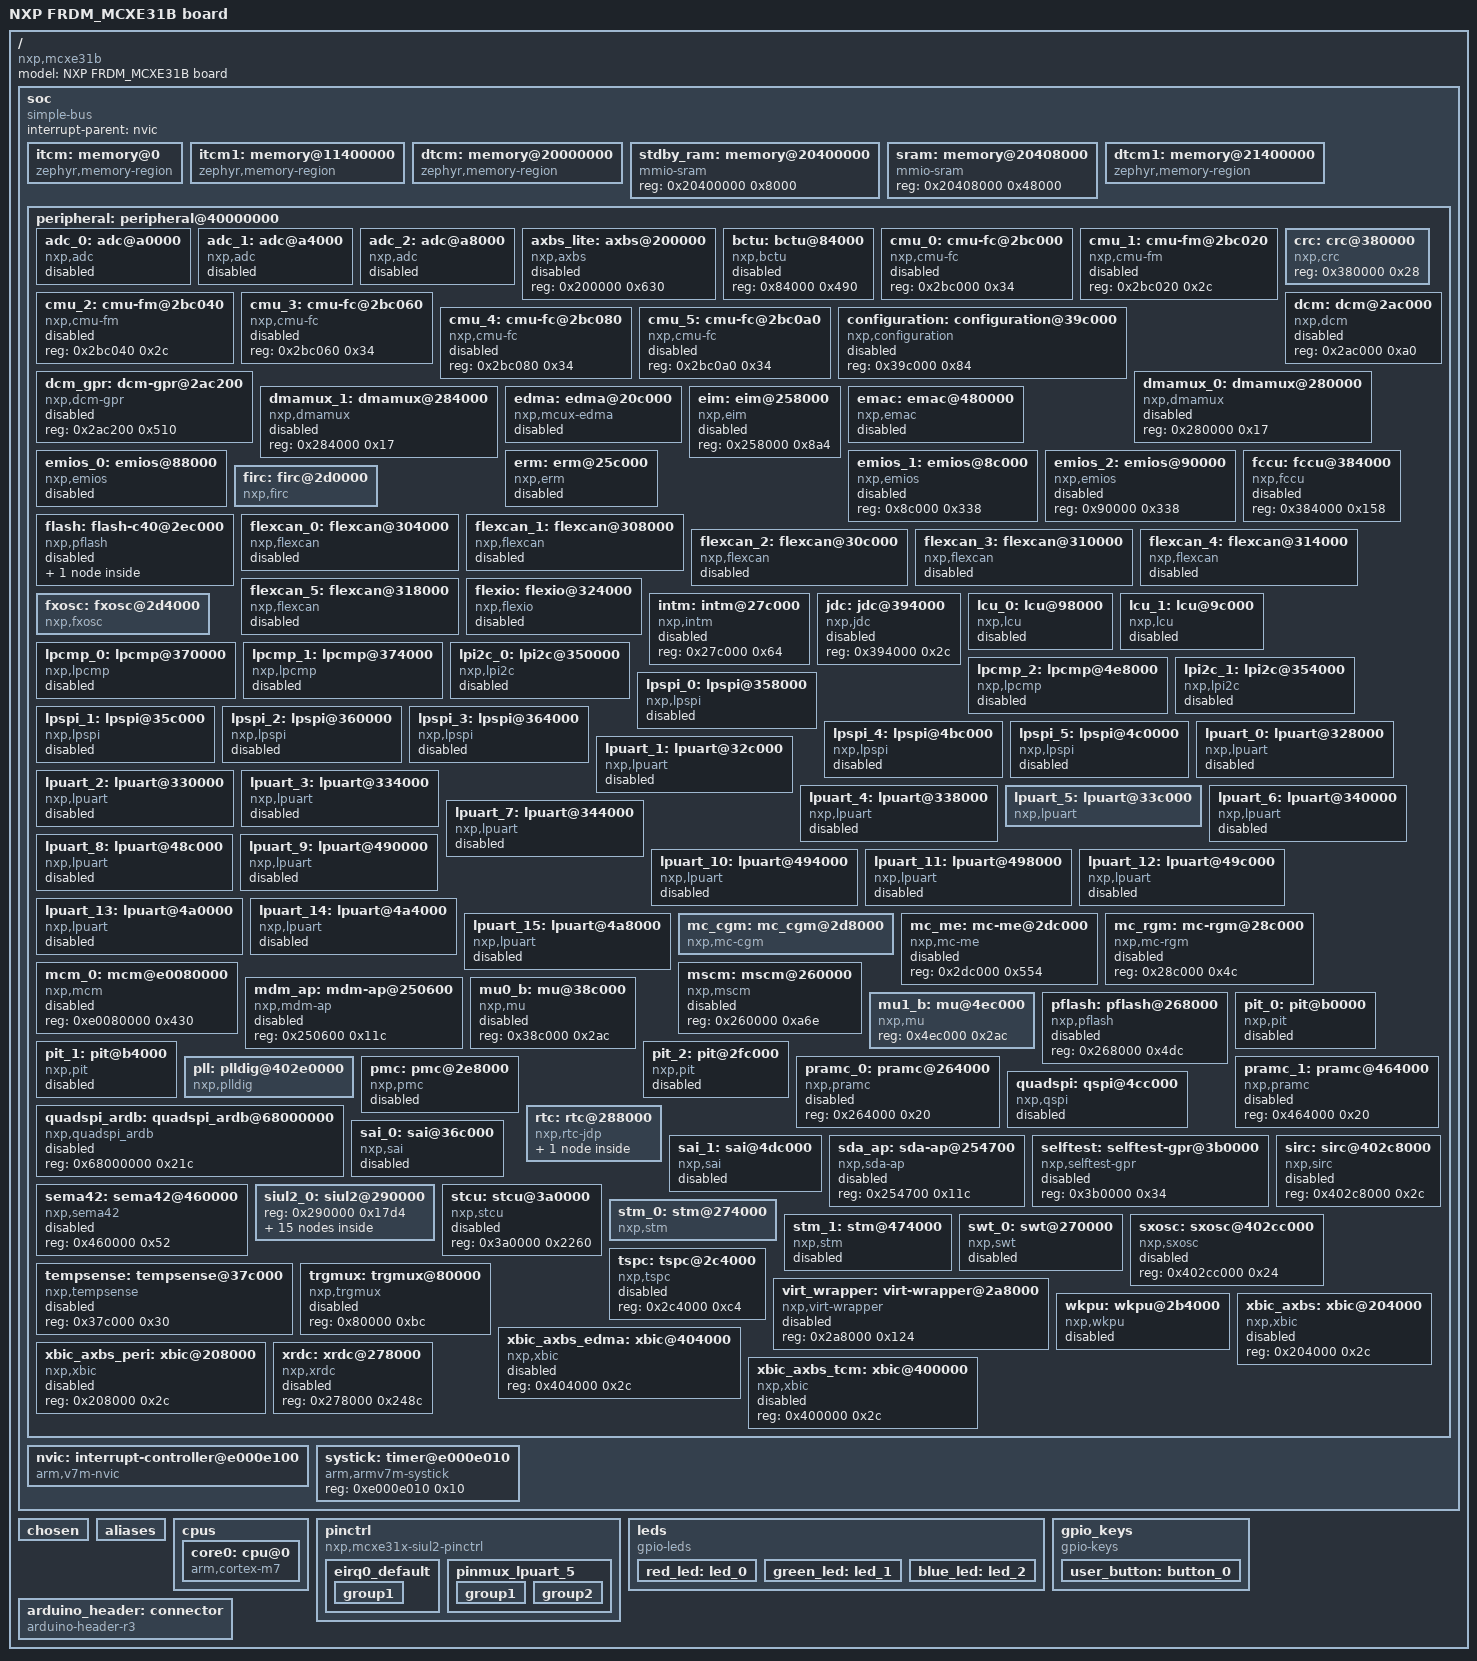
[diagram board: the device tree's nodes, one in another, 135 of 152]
/dts-v1/;

/* node '/' defined in zephyr/dts/arm/nxp/nxp_mcxe31b.dtsi:10 */
/ {
	#address-cells = < 0x1 >;         /* in zephyr/dts/common/skeleton.dtsi:10 */
	#size-cells = < 0x1 >;            /* in zephyr/dts/common/skeleton.dtsi:11 */
	model = "NXP FRDM_MCXE31B board"; /* in zephyr/boards/nxp/frdm_mcxe31b/frdm_mcxe31b.dts:16 */
	compatible = "nxp,mcxe31b";       /* in zephyr/boards/nxp/frdm_mcxe31b/frdm_mcxe31b.dts:17 */

	/* node '/soc' defined in zephyr/dts/arm/nxp/nxp_mcxe31b.dtsi:11 */
	soc {
		#address-cells = < 0x1 >;     /* in zephyr/dts/arm/armv7-m.dtsi:7 */
		#size-cells = < 0x1 >;        /* in zephyr/dts/arm/armv7-m.dtsi:8 */
		compatible = "simple-bus";    /* in zephyr/dts/arm/armv7-m.dtsi:9 */
		interrupt-parent = < &nvic >; /* in zephyr/dts/arm/armv7-m.dtsi:10 */
		ranges;                       /* in zephyr/dts/arm/armv7-m.dtsi:11 */

		/* node '/soc/memory@0' defined in zephyr/dts/arm/nxp/nxp_mcxe31b.dtsi:12 */
		itcm: memory@0 {
			compatible = "zephyr,memory-region",
			             "mmio-sram";            /* in zephyr/dts/arm/nxp/nxp_mcxe31b.dtsi:13 */
			reg = < 0x0 0x8000 >;                /* in zephyr/dts/arm/nxp/nxp_mcxe31b.dtsi:14 */
			zephyr,memory-region = "ITCM";       /* in zephyr/dts/arm/nxp/nxp_mcxe31b.dtsi:15 */
		};

		/* node '/soc/memory@11400000' defined in zephyr/dts/arm/nxp/nxp_mcxe31b.dtsi:18 */
		itcm1: memory@11400000 {
			compatible = "zephyr,memory-region",
			             "mmio-sram";            /* in zephyr/dts/arm/nxp/nxp_mcxe31b.dtsi:19 */
			reg = < 0x11400000 0x8000 >;         /* in zephyr/dts/arm/nxp/nxp_mcxe31b.dtsi:20 */
			zephyr,memory-region = "ITCM1";      /* in zephyr/dts/arm/nxp/nxp_mcxe31b.dtsi:21 */
		};

		/* node '/soc/memory@20000000' defined in zephyr/dts/arm/nxp/nxp_mcxe31b.dtsi:24 */
		dtcm: memory@20000000 {
			compatible = "zephyr,memory-region",
			             "mmio-sram";            /* in zephyr/dts/arm/nxp/nxp_mcxe31b.dtsi:25 */
			reg = < 0x20000000 0x10000 >;        /* in zephyr/dts/arm/nxp/nxp_mcxe31b.dtsi:26 */
			zephyr,memory-region = "DTCM";       /* in zephyr/dts/arm/nxp/nxp_mcxe31b.dtsi:27 */
		};

		/* node '/soc/memory@20400000' defined in zephyr/dts/arm/nxp/nxp_mcxe31b.dtsi:31 */
		stdby_ram: memory@20400000 {
			compatible = "mmio-sram";    /* in zephyr/dts/arm/nxp/nxp_mcxe31b.dtsi:32 */
			reg = < 0x20400000 0x8000 >; /* in zephyr/dts/arm/nxp/nxp_mcxe31b.dtsi:33 */
		};

		/* node '/soc/memory@20408000' defined in zephyr/dts/arm/nxp/nxp_mcxe31b.dtsi:37 */
		sram: memory@20408000 {
			compatible = "mmio-sram";     /* in zephyr/dts/arm/nxp/nxp_mcxe31b.dtsi:38 */
			reg = < 0x20408000 0x48000 >; /* in zephyr/dts/arm/nxp/nxp_mcxe31b.dtsi:39 */
		};

		/* node '/soc/memory@21400000' defined in zephyr/dts/arm/nxp/nxp_mcxe31b.dtsi:42 */
		dtcm1: memory@21400000 {
			compatible = "zephyr,memory-region",
			             "mmio-sram";            /* in zephyr/dts/arm/nxp/nxp_mcxe31b.dtsi:43 */
			reg = < 0x21400000 0x10000 >;        /* in zephyr/dts/arm/nxp/nxp_mcxe31b.dtsi:44 */
			zephyr,memory-region = "DTCM1";      /* in zephyr/dts/arm/nxp/nxp_mcxe31b.dtsi:45 */
		};

		/* node '/soc/peripheral@40000000' defined in zephyr/dts/arm/nxp/nxp_mcxe31b.dtsi:48 */
		peripheral: peripheral@40000000 {
			ranges = < 0x0 0x40000000 0x10000000 >; /* in zephyr/dts/arm/nxp/nxp_mcxe31b.dtsi:49 */
			#address-cells = < 0x1 >;               /* in zephyr/dts/arm/nxp/nxp_mcxe31x_common.dtsi:31 */
			#size-cells = < 0x1 >;                  /* in zephyr/dts/arm/nxp/nxp_mcxe31x_common.dtsi:32 */

			/* node '/soc/peripheral@40000000/adc@a0000' defined in zephyr/dts/arm/nxp/nxp_mcxe31x_common.dtsi:34 */
			adc_0: adc@a0000 {
				compatible = "nxp,adc";    /* in zephyr/dts/arm/nxp/nxp_mcxe31x_common.dtsi:35 */
				reg = < 0xa0000 0x3d4 >;   /* in zephyr/dts/arm/nxp/nxp_mcxe31x_common.dtsi:36 */
				interrupts = < 0xb4 0x0 >; /* in zephyr/dts/arm/nxp/nxp_mcxe31x_common.dtsi:37 */
				status = "disabled";       /* in zephyr/dts/arm/nxp/nxp_mcxe31x_common.dtsi:38 */
			};

			/* node '/soc/peripheral@40000000/adc@a4000' defined in zephyr/dts/arm/nxp/nxp_mcxe31x_common.dtsi:41 */
			adc_1: adc@a4000 {
				compatible = "nxp,adc";    /* in zephyr/dts/arm/nxp/nxp_mcxe31x_common.dtsi:42 */
				reg = < 0xa4000 0x3d4 >;   /* in zephyr/dts/arm/nxp/nxp_mcxe31x_common.dtsi:43 */
				interrupts = < 0xb5 0x0 >; /* in zephyr/dts/arm/nxp/nxp_mcxe31x_common.dtsi:44 */
				status = "disabled";       /* in zephyr/dts/arm/nxp/nxp_mcxe31x_common.dtsi:45 */
			};

			/* node '/soc/peripheral@40000000/adc@a8000' defined in zephyr/dts/arm/nxp/nxp_mcxe31x_common.dtsi:48 */
			adc_2: adc@a8000 {
				compatible = "nxp,adc";    /* in zephyr/dts/arm/nxp/nxp_mcxe31x_common.dtsi:49 */
				reg = < 0xa8000 0x3d4 >;   /* in zephyr/dts/arm/nxp/nxp_mcxe31x_common.dtsi:50 */
				interrupts = < 0xb6 0x0 >; /* in zephyr/dts/arm/nxp/nxp_mcxe31x_common.dtsi:51 */
				status = "disabled";       /* in zephyr/dts/arm/nxp/nxp_mcxe31x_common.dtsi:52 */
			};

			/* node '/soc/peripheral@40000000/axbs@200000' defined in zephyr/dts/arm/nxp/nxp_mcxe31x_common.dtsi:55 */
			axbs_lite: axbs@200000 {
				compatible = "nxp,axbs";  /* in zephyr/dts/arm/nxp/nxp_mcxe31x_common.dtsi:56 */
				reg = < 0x200000 0x630 >; /* in zephyr/dts/arm/nxp/nxp_mcxe31x_common.dtsi:57 */
				status = "disabled";      /* in zephyr/dts/arm/nxp/nxp_mcxe31x_common.dtsi:58 */
			};

			/* node '/soc/peripheral@40000000/bctu@84000' defined in zephyr/dts/arm/nxp/nxp_mcxe31x_common.dtsi:61 */
			bctu: bctu@84000 {
				compatible = "nxp,bctu"; /* in zephyr/dts/arm/nxp/nxp_mcxe31x_common.dtsi:62 */
				reg = < 0x84000 0x490 >; /* in zephyr/dts/arm/nxp/nxp_mcxe31x_common.dtsi:63 */
				status = "disabled";     /* in zephyr/dts/arm/nxp/nxp_mcxe31x_common.dtsi:64 */
			};

			/* node '/soc/peripheral@40000000/cmu-fc@2bc000' defined in zephyr/dts/arm/nxp/nxp_mcxe31x_common.dtsi:67 */
			cmu_0: cmu-fc@2bc000 {
				compatible = "nxp,cmu-fc"; /* in zephyr/dts/arm/nxp/nxp_mcxe31x_common.dtsi:68 */
				reg = < 0x2bc000 0x34 >;   /* in zephyr/dts/arm/nxp/nxp_mcxe31x_common.dtsi:69 */
				status = "disabled";       /* in zephyr/dts/arm/nxp/nxp_mcxe31x_common.dtsi:70 */
			};

			/* node '/soc/peripheral@40000000/cmu-fm@2bc020' defined in zephyr/dts/arm/nxp/nxp_mcxe31x_common.dtsi:73 */
			cmu_1: cmu-fm@2bc020 {
				compatible = "nxp,cmu-fm"; /* in zephyr/dts/arm/nxp/nxp_mcxe31x_common.dtsi:74 */
				reg = < 0x2bc020 0x2c >;   /* in zephyr/dts/arm/nxp/nxp_mcxe31x_common.dtsi:75 */
				status = "disabled";       /* in zephyr/dts/arm/nxp/nxp_mcxe31x_common.dtsi:76 */
			};

			/* node '/soc/peripheral@40000000/cmu-fm@2bc040' defined in zephyr/dts/arm/nxp/nxp_mcxe31x_common.dtsi:79 */
			cmu_2: cmu-fm@2bc040 {
				compatible = "nxp,cmu-fm"; /* in zephyr/dts/arm/nxp/nxp_mcxe31x_common.dtsi:80 */
				reg = < 0x2bc040 0x2c >;   /* in zephyr/dts/arm/nxp/nxp_mcxe31x_common.dtsi:81 */
				status = "disabled";       /* in zephyr/dts/arm/nxp/nxp_mcxe31x_common.dtsi:82 */
			};

			/* node '/soc/peripheral@40000000/cmu-fc@2bc060' defined in zephyr/dts/arm/nxp/nxp_mcxe31x_common.dtsi:85 */
			cmu_3: cmu-fc@2bc060 {
				compatible = "nxp,cmu-fc"; /* in zephyr/dts/arm/nxp/nxp_mcxe31x_common.dtsi:86 */
				reg = < 0x2bc060 0x34 >;   /* in zephyr/dts/arm/nxp/nxp_mcxe31x_common.dtsi:87 */
				status = "disabled";       /* in zephyr/dts/arm/nxp/nxp_mcxe31x_common.dtsi:88 */
			};

			/* node '/soc/peripheral@40000000/cmu-fc@2bc080' defined in zephyr/dts/arm/nxp/nxp_mcxe31x_common.dtsi:91 */
			cmu_4: cmu-fc@2bc080 {
				compatible = "nxp,cmu-fc"; /* in zephyr/dts/arm/nxp/nxp_mcxe31x_common.dtsi:92 */
				reg = < 0x2bc080 0x34 >;   /* in zephyr/dts/arm/nxp/nxp_mcxe31x_common.dtsi:93 */
				status = "disabled";       /* in zephyr/dts/arm/nxp/nxp_mcxe31x_common.dtsi:94 */
			};

			/* node '/soc/peripheral@40000000/cmu-fc@2bc0a0' defined in zephyr/dts/arm/nxp/nxp_mcxe31x_common.dtsi:97 */
			cmu_5: cmu-fc@2bc0a0 {
				compatible = "nxp,cmu-fc"; /* in zephyr/dts/arm/nxp/nxp_mcxe31x_common.dtsi:98 */
				reg = < 0x2bc0a0 0x34 >;   /* in zephyr/dts/arm/nxp/nxp_mcxe31x_common.dtsi:99 */
				status = "disabled";       /* in zephyr/dts/arm/nxp/nxp_mcxe31x_common.dtsi:100 */
			};

			/* node '/soc/peripheral@40000000/configuration@39c000' defined in zephyr/dts/arm/nxp/nxp_mcxe31x_common.dtsi:103 */
			configuration: configuration@39c000 {
				compatible = "nxp,configuration"; /* in zephyr/dts/arm/nxp/nxp_mcxe31x_common.dtsi:104 */
				reg = < 0x39c000 0x84 >;          /* in zephyr/dts/arm/nxp/nxp_mcxe31x_common.dtsi:105 */
				status = "disabled";              /* in zephyr/dts/arm/nxp/nxp_mcxe31x_common.dtsi:106 */
			};

			/* node '/soc/peripheral@40000000/crc@380000' defined in zephyr/dts/arm/nxp/nxp_mcxe31x_common.dtsi:109 */
			crc: crc@380000 {
				compatible = "nxp,crc";  /* in zephyr/dts/arm/nxp/nxp_mcxe31x_common.dtsi:110 */
				reg = < 0x380000 0x28 >; /* in zephyr/dts/arm/nxp/nxp_mcxe31x_common.dtsi:111 */
			};

			/* node '/soc/peripheral@40000000/dcm@2ac000' defined in zephyr/dts/arm/nxp/nxp_mcxe31x_common.dtsi:114 */
			dcm: dcm@2ac000 {
				compatible = "nxp,dcm";  /* in zephyr/dts/arm/nxp/nxp_mcxe31x_common.dtsi:115 */
				reg = < 0x2ac000 0xa0 >; /* in zephyr/dts/arm/nxp/nxp_mcxe31x_common.dtsi:116 */
				status = "disabled";     /* in zephyr/dts/arm/nxp/nxp_mcxe31x_common.dtsi:117 */
			};

			/* node '/soc/peripheral@40000000/dcm-gpr@2ac200' defined in zephyr/dts/arm/nxp/nxp_mcxe31x_common.dtsi:120 */
			dcm_gpr: dcm-gpr@2ac200 {
				compatible = "nxp,dcm-gpr"; /* in zephyr/dts/arm/nxp/nxp_mcxe31x_common.dtsi:121 */
				reg = < 0x2ac200 0x510 >;   /* in zephyr/dts/arm/nxp/nxp_mcxe31x_common.dtsi:122 */
				status = "disabled";        /* in zephyr/dts/arm/nxp/nxp_mcxe31x_common.dtsi:123 */
			};

			/* node '/soc/peripheral@40000000/dmamux@280000' defined in zephyr/dts/arm/nxp/nxp_mcxe31x_common.dtsi:126 */
			dmamux_0: dmamux@280000 {
				compatible = "nxp,dmamux"; /* in zephyr/dts/arm/nxp/nxp_mcxe31x_common.dtsi:127 */
				reg = < 0x280000 0x17 >;   /* in zephyr/dts/arm/nxp/nxp_mcxe31x_common.dtsi:128 */
				status = "disabled";       /* in zephyr/dts/arm/nxp/nxp_mcxe31x_common.dtsi:129 */
			};

			/* node '/soc/peripheral@40000000/dmamux@284000' defined in zephyr/dts/arm/nxp/nxp_mcxe31x_common.dtsi:132 */
			dmamux_1: dmamux@284000 {
				compatible = "nxp,dmamux"; /* in zephyr/dts/arm/nxp/nxp_mcxe31x_common.dtsi:133 */
				reg = < 0x284000 0x17 >;   /* in zephyr/dts/arm/nxp/nxp_mcxe31x_common.dtsi:134 */
				status = "disabled";       /* in zephyr/dts/arm/nxp/nxp_mcxe31x_common.dtsi:135 */
			};

			/* node '/soc/peripheral@40000000/edma@20c000' defined in zephyr/dts/arm/nxp/nxp_mcxe31x_common.dtsi:138 */
			edma: edma@20c000 {
				#dma-cells = < 0x2 >;         /* in zephyr/dts/arm/nxp/nxp_mcxe31x_common.dtsi:139 */
				compatible = "nxp,mcux-edma"; /* in zephyr/dts/arm/nxp/nxp_mcxe31x_common.dtsi:140 */
				reg = < 0x20c000 0x19c >;     /* in zephyr/dts/arm/nxp/nxp_mcxe31x_common.dtsi:141 */
				dma-channels = < 0x20 >;      /* in zephyr/dts/arm/nxp/nxp_mcxe31x_common.dtsi:142 */
				dma-requests = < 0x80 >;      /* in zephyr/dts/arm/nxp/nxp_mcxe31x_common.dtsi:143 */
				interrupts = < 0x4 0x0 >,
				             < 0x5 0x0 >,
				             < 0x6 0x0 >,
				             < 0x7 0x0 >,
				             < 0x8 0x0 >,
				             < 0x9 0x0 >,
				             < 0xa 0x0 >,
				             < 0xb 0x0 >,
				             < 0xc 0x0 >,
				             < 0xd 0x0 >,
				             < 0xe 0x0 >,
				             < 0xf 0x0 >,
				             < 0x10 0x0 >,
				             < 0x11 0x0 >,
				             < 0x12 0x0 >,
				             < 0x13 0x0 >,
				             < 0x14 0x0 >,
				             < 0x15 0x0 >,
				             < 0x16 0x0 >,
				             < 0x17 0x0 >,
				             < 0x18 0x0 >,
				             < 0x19 0x0 >,
				             < 0x1a 0x0 >,
				             < 0x1b 0x0 >,
				             < 0x1c 0x0 >,
				             < 0x1d 0x0 >,
				             < 0x1e 0x0 >,
				             < 0x1f 0x0 >,
				             < 0x20 0x0 >,
				             < 0x21 0x0 >,
				             < 0x22 0x0 >,
				             < 0x23 0x0 >;    /* in zephyr/dts/arm/nxp/nxp_mcxe31x_common.dtsi:144 */
				status = "disabled";          /* in zephyr/dts/arm/nxp/nxp_mcxe31x_common.dtsi:152 */
				phandle = < 0x4 >;            /* in zephyr/boards/nxp/frdm_mcxe31b/frdm_mcxe31b.dts:109 */
			};

			/* node '/soc/peripheral@40000000/eim@258000' defined in zephyr/dts/arm/nxp/nxp_mcxe31x_common.dtsi:155 */
			eim: eim@258000 {
				compatible = "nxp,eim";   /* in zephyr/dts/arm/nxp/nxp_mcxe31x_common.dtsi:156 */
				reg = < 0x258000 0x8a4 >; /* in zephyr/dts/arm/nxp/nxp_mcxe31x_common.dtsi:157 */
				status = "disabled";      /* in zephyr/dts/arm/nxp/nxp_mcxe31x_common.dtsi:158 */
			};

			/* node '/soc/peripheral@40000000/emac@480000' defined in zephyr/dts/arm/nxp/nxp_mcxe31x_common.dtsi:161 */
			emac: emac@480000 {
				compatible = "nxp,emac";   /* in zephyr/dts/arm/nxp/nxp_mcxe31x_common.dtsi:162 */
				reg = < 0x480000 0x120c >; /* in zephyr/dts/arm/nxp/nxp_mcxe31x_common.dtsi:163 */
				interrupts = < 0x69 0x0 >; /* in zephyr/dts/arm/nxp/nxp_mcxe31x_common.dtsi:164 */
				status = "disabled";       /* in zephyr/dts/arm/nxp/nxp_mcxe31x_common.dtsi:165 */
			};

			/* node '/soc/peripheral@40000000/emios@88000' defined in zephyr/dts/arm/nxp/nxp_mcxe31x_common.dtsi:168 */
			emios_0: emios@88000 {
				compatible = "nxp,emios";     /* in zephyr/dts/arm/nxp/nxp_mcxe31x_common.dtsi:169 */
				reg = < 0x88000 0x338 >;      /* in zephyr/dts/arm/nxp/nxp_mcxe31x_common.dtsi:170 */
				interrupts = < 0x3d 0x0 >,
				             < 0x3e 0x0 >,
				             < 0x3f 0x0 >,
				             < 0x40 0x0 >,
				             < 0x41 0x0 >,
				             < 0x42 0x0 >;    /* in zephyr/dts/arm/nxp/nxp_mcxe31x_common.dtsi:171 */
				interrupt-names = "emios0-2",
				                  "emios0-3",
				                  "emios0-4",
				                  "emios0-5",
				                  "emios0-6",
				                  "emios0-7"; /* in zephyr/dts/arm/nxp/nxp_mcxe31x_common.dtsi:173 */
				status = "disabled";          /* in zephyr/dts/arm/nxp/nxp_mcxe31x_common.dtsi:175 */
			};

			/* node '/soc/peripheral@40000000/emios@8c000' defined in zephyr/dts/arm/nxp/nxp_mcxe31x_common.dtsi:178 */
			emios_1: emios@8c000 {
				compatible = "nxp,emios"; /* in zephyr/dts/arm/nxp/nxp_mcxe31x_common.dtsi:179 */
				reg = < 0x8c000 0x338 >;  /* in zephyr/dts/arm/nxp/nxp_mcxe31x_common.dtsi:180 */
				status = "disabled";      /* in zephyr/dts/arm/nxp/nxp_mcxe31x_common.dtsi:181 */
			};

			/* node '/soc/peripheral@40000000/emios@90000' defined in zephyr/dts/arm/nxp/nxp_mcxe31x_common.dtsi:184 */
			emios_2: emios@90000 {
				compatible = "nxp,emios"; /* in zephyr/dts/arm/nxp/nxp_mcxe31x_common.dtsi:185 */
				reg = < 0x90000 0x338 >;  /* in zephyr/dts/arm/nxp/nxp_mcxe31x_common.dtsi:186 */
				status = "disabled";      /* in zephyr/dts/arm/nxp/nxp_mcxe31x_common.dtsi:187 */
			};

			/* node '/soc/peripheral@40000000/erm@25c000' defined in zephyr/dts/arm/nxp/nxp_mcxe31x_common.dtsi:190 */
			erm: erm@25c000 {
				compatible = "nxp,erm";    /* in zephyr/dts/arm/nxp/nxp_mcxe31x_common.dtsi:191 */
				reg = < 0x25c000 0x258 >;  /* in zephyr/dts/arm/nxp/nxp_mcxe31x_common.dtsi:192 */
				interrupts = < 0x24 0x0 >,
				             < 0x25 0x0 >; /* in zephyr/dts/arm/nxp/nxp_mcxe31x_common.dtsi:193 */
				interrupt-names = "erm-0",
				                  "erm-1"; /* in zephyr/dts/arm/nxp/nxp_mcxe31x_common.dtsi:194 */
				status = "disabled";       /* in zephyr/dts/arm/nxp/nxp_mcxe31x_common.dtsi:195 */
			};

			/* node '/soc/peripheral@40000000/fccu@384000' defined in zephyr/dts/arm/nxp/nxp_mcxe31x_common.dtsi:198 */
			fccu: fccu@384000 {
				compatible = "nxp,fccu";  /* in zephyr/dts/arm/nxp/nxp_mcxe31x_common.dtsi:199 */
				reg = < 0x384000 0x158 >; /* in zephyr/dts/arm/nxp/nxp_mcxe31x_common.dtsi:200 */
				status = "disabled";      /* in zephyr/dts/arm/nxp/nxp_mcxe31x_common.dtsi:201 */
			};

			/* node '/soc/peripheral@40000000/firc@2d0000' defined in zephyr/dts/arm/nxp/nxp_mcxe31x_common.dtsi:204 */
			firc: firc@2d0000 {
				compatible = "nxp,firc"; /* in zephyr/dts/arm/nxp/nxp_mcxe31x_common.dtsi:205 */
				reg = < 0x2d0000 0x28 >; /* in zephyr/dts/arm/nxp/nxp_mcxe31x_common.dtsi:206 */
				status = "okay";         /* in zephyr/boards/nxp/frdm_mcxe31b/frdm_mcxe31b.dts:132 */
				firc-div = "UnDiv";      /* in zephyr/boards/nxp/frdm_mcxe31b/frdm_mcxe31b.dts:133 */
			};

			/* node '/soc/peripheral@40000000/flash-c40@2ec000' defined in zephyr/dts/arm/nxp/nxp_mcxe31x_common.dtsi:210 */
			flash: flash-c40@2ec000 {
				compatible = "nxp,pflash";   /* in zephyr/dts/arm/nxp/nxp_mcxe31x_common.dtsi:211 */
				reg = < 0x2ec000 0x19c >;    /* in zephyr/dts/arm/nxp/nxp_mcxe31x_common.dtsi:212 */
				interrupts = < 0x30 0x0 >,
				             < 0x31 0x0 >,
				             < 0x32 0x0 >;   /* in zephyr/dts/arm/nxp/nxp_mcxe31x_common.dtsi:213 */
				interrupt-names = "flash-0",
				                  "flash-1",
				                  "flash-2"; /* in zephyr/dts/arm/nxp/nxp_mcxe31x_common.dtsi:214 */
				#address-cells = < 0x1 >;    /* in zephyr/dts/arm/nxp/nxp_mcxe31x_common.dtsi:215 */
				#size-cells = < 0x1 >;       /* in zephyr/dts/arm/nxp/nxp_mcxe31x_common.dtsi:216 */
				status = "disabled";         /* in zephyr/dts/arm/nxp/nxp_mcxe31x_common.dtsi:217 */

				/* node '/soc/peripheral@40000000/flash-c40@2ec000/memory@400000' defined in zephyr/dts/arm/nxp/nxp_mcxe31x_common.dtsi:219 */
				program_flash: memory@400000 {
					compatible = "soc-nv-flash"; /* in zephyr/dts/arm/nxp/nxp_mcxe31x_common.dtsi:220 */
					reg = < 0x400000 0x400000 >; /* in zephyr/dts/arm/nxp/nxp_mcxe31x_common.dtsi:221 */
				};
			};

			/* node '/soc/peripheral@40000000/flexcan@304000' defined in zephyr/dts/arm/nxp/nxp_mcxe31x_common.dtsi:225 */
			flexcan_0: flexcan@304000 {
				compatible = "nxp,flexcan";     /* in zephyr/dts/arm/nxp/nxp_mcxe31x_common.dtsi:226 */
				reg = < 0x304000 0x321c >;      /* in zephyr/dts/arm/nxp/nxp_mcxe31x_common.dtsi:227 */
				interrupts = < 0x6d 0x0 >,
				             < 0x6e 0x0 >,
				             < 0x6f 0x0 >,
				             < 0x70 0x0 >;      /* in zephyr/dts/arm/nxp/nxp_mcxe31x_common.dtsi:228 */
				interrupt-names = "flexcan0-0",
				                  "flexcan0-1",
				                  "flexcan0-2",
				                  "flexcan0-3"; /* in zephyr/dts/arm/nxp/nxp_mcxe31x_common.dtsi:229 */
				clocks = < &mc_cgm 0x2400 >;    /* in zephyr/dts/arm/nxp/nxp_mcxe31x_common.dtsi:230 */
				clk-source = < 0x0 >;           /* in zephyr/dts/arm/nxp/nxp_mcxe31x_common.dtsi:231 */
				status = "disabled";            /* in zephyr/dts/arm/nxp/nxp_mcxe31x_common.dtsi:232 */
			};

			/* node '/soc/peripheral@40000000/flexcan@308000' defined in zephyr/dts/arm/nxp/nxp_mcxe31x_common.dtsi:235 */
			flexcan_1: flexcan@308000 {
				compatible = "nxp,flexcan";     /* in zephyr/dts/arm/nxp/nxp_mcxe31x_common.dtsi:236 */
				reg = < 0x308000 0xd4c >;       /* in zephyr/dts/arm/nxp/nxp_mcxe31x_common.dtsi:237 */
				interrupts = < 0x71 0x0 >,
				             < 0x72 0x0 >,
				             < 0x73 0x0 >;      /* in zephyr/dts/arm/nxp/nxp_mcxe31x_common.dtsi:238 */
				interrupt-names = "flexcan1-0",
				                  "flexcan1-1",
				                  "flexcan1-2"; /* in zephyr/dts/arm/nxp/nxp_mcxe31x_common.dtsi:239 */
				clocks = < &mc_cgm 0x2401 >;    /* in zephyr/dts/arm/nxp/nxp_mcxe31x_common.dtsi:240 */
				clk-source = < 0x0 >;           /* in zephyr/dts/arm/nxp/nxp_mcxe31x_common.dtsi:241 */
				status = "disabled";            /* in zephyr/dts/arm/nxp/nxp_mcxe31x_common.dtsi:242 */
			};

			/* node '/soc/peripheral@40000000/flexcan@30c000' defined in zephyr/dts/arm/nxp/nxp_mcxe31x_common.dtsi:245 */
			flexcan_2: flexcan@30c000 {
				compatible = "nxp,flexcan";     /* in zephyr/dts/arm/nxp/nxp_mcxe31x_common.dtsi:246 */
				reg = < 0x30c000 0xd4c >;       /* in zephyr/dts/arm/nxp/nxp_mcxe31x_common.dtsi:247 */
				interrupts = < 0x74 0x0 >,
				             < 0x75 0x0 >,
				             < 0x76 0x0 >;      /* in zephyr/dts/arm/nxp/nxp_mcxe31x_common.dtsi:248 */
				interrupt-names = "flexcan2-0",
				                  "flexcan2-1",
				                  "flexcan2-2"; /* in zephyr/dts/arm/nxp/nxp_mcxe31x_common.dtsi:249 */
				clocks = < &mc_cgm 0x2402 >;    /* in zephyr/dts/arm/nxp/nxp_mcxe31x_common.dtsi:250 */
				clk-source = < 0x0 >;           /* in zephyr/dts/arm/nxp/nxp_mcxe31x_common.dtsi:251 */
				status = "disabled";            /* in zephyr/dts/arm/nxp/nxp_mcxe31x_common.dtsi:252 */
			};

			/* node '/soc/peripheral@40000000/flexcan@310000' defined in zephyr/dts/arm/nxp/nxp_mcxe31x_common.dtsi:255 */
			flexcan_3: flexcan@310000 {
				compatible = "nxp,flexcan";     /* in zephyr/dts/arm/nxp/nxp_mcxe31x_common.dtsi:256 */
				reg = < 0x310000 0xccc >;       /* in zephyr/dts/arm/nxp/nxp_mcxe31x_common.dtsi:257 */
				interrupts = < 0x77 0x0 >,
				             < 0x78 0x0 >;      /* in zephyr/dts/arm/nxp/nxp_mcxe31x_common.dtsi:258 */
				interrupt-names = "flexcan3-0",
				                  "flexcan3-1"; /* in zephyr/dts/arm/nxp/nxp_mcxe31x_common.dtsi:259 */
				clocks = < &mc_cgm 0x2403 >;    /* in zephyr/dts/arm/nxp/nxp_mcxe31x_common.dtsi:260 */
				clk-source = < 0x0 >;           /* in zephyr/dts/arm/nxp/nxp_mcxe31x_common.dtsi:261 */
				status = "disabled";            /* in zephyr/dts/arm/nxp/nxp_mcxe31x_common.dtsi:262 */
			};

			/* node '/soc/peripheral@40000000/flexcan@314000' defined in zephyr/dts/arm/nxp/nxp_mcxe31x_common.dtsi:265 */
			flexcan_4: flexcan@314000 {
				compatible = "nxp,flexcan";     /* in zephyr/dts/arm/nxp/nxp_mcxe31x_common.dtsi:266 */
				reg = < 0x314000 0xccc >;       /* in zephyr/dts/arm/nxp/nxp_mcxe31x_common.dtsi:267 */
				interrupts = < 0x79 0x0 >,
				             < 0x7a 0x0 >;      /* in zephyr/dts/arm/nxp/nxp_mcxe31x_common.dtsi:268 */
				interrupt-names = "flexcan4-0",
				                  "flexcan4-1"; /* in zephyr/dts/arm/nxp/nxp_mcxe31x_common.dtsi:269 */
				clocks = < &mc_cgm 0x2404 >;    /* in zephyr/dts/arm/nxp/nxp_mcxe31x_common.dtsi:270 */
				clk-source = < 0x0 >;           /* in zephyr/dts/arm/nxp/nxp_mcxe31x_common.dtsi:271 */
				status = "disabled";            /* in zephyr/dts/arm/nxp/nxp_mcxe31x_common.dtsi:272 */
			};

			/* node '/soc/peripheral@40000000/flexcan@318000' defined in zephyr/dts/arm/nxp/nxp_mcxe31x_common.dtsi:275 */
			flexcan_5: flexcan@318000 {
				compatible = "nxp,flexcan";     /* in zephyr/dts/arm/nxp/nxp_mcxe31x_common.dtsi:276 */
				reg = < 0x318000 0xccc >;       /* in zephyr/dts/arm/nxp/nxp_mcxe31x_common.dtsi:277 */
				interrupts = < 0x7b 0x0 >,
				             < 0x7c 0x0 >;      /* in zephyr/dts/arm/nxp/nxp_mcxe31x_common.dtsi:278 */
				interrupt-names = "flexcan5-0",
				                  "flexcan5-1"; /* in zephyr/dts/arm/nxp/nxp_mcxe31x_common.dtsi:279 */
				clocks = < &mc_cgm 0x2405 >;    /* in zephyr/dts/arm/nxp/nxp_mcxe31x_common.dtsi:280 */
				clk-source = < 0x0 >;           /* in zephyr/dts/arm/nxp/nxp_mcxe31x_common.dtsi:281 */
				status = "disabled";            /* in zephyr/dts/arm/nxp/nxp_mcxe31x_common.dtsi:282 */
			};

			/* node '/soc/peripheral@40000000/flexio@324000' defined in zephyr/dts/arm/nxp/nxp_mcxe31x_common.dtsi:285 */
			flexio: flexio@324000 {
				compatible = "nxp,flexio";   /* in zephyr/dts/arm/nxp/nxp_mcxe31x_common.dtsi:286 */
				reg = < 0x324000 0x93c >;    /* in zephyr/dts/arm/nxp/nxp_mcxe31x_common.dtsi:287 */
				interrupts = < 0x8b 0x0 >;   /* in zephyr/dts/arm/nxp/nxp_mcxe31x_common.dtsi:288 */
				clocks = < &mc_cgm 0x2500 >; /* in zephyr/dts/arm/nxp/nxp_mcxe31x_common.dtsi:289 */
				status = "disabled";         /* in zephyr/dts/arm/nxp/nxp_mcxe31x_common.dtsi:290 */
			};

			/* node '/soc/peripheral@40000000/fxosc@2d4000' defined in zephyr/dts/arm/nxp/nxp_mcxe31x_common.dtsi:293 */
			fxosc: fxosc@2d4000 {
				compatible = "nxp,fxosc"; /* in zephyr/dts/arm/nxp/nxp_mcxe31x_common.dtsi:294 */
				reg = < 0x2d4000 0x24 >;  /* in zephyr/dts/arm/nxp/nxp_mcxe31x_common.dtsi:295 */
				status = "okay";          /* in zephyr/boards/nxp/frdm_mcxe31b/frdm_mcxe31b.dts:137 */
				freq = < 0xf42400 >;      /* in zephyr/boards/nxp/frdm_mcxe31b/frdm_mcxe31b.dts:138 */
				workmode = "crystal";     /* in zephyr/boards/nxp/frdm_mcxe31b/frdm_mcxe31b.dts:139 */
				delay = < 0x31 >;         /* in zephyr/boards/nxp/frdm_mcxe31b/frdm_mcxe31b.dts:140 */
				overdrive = < 0xc >;      /* in zephyr/boards/nxp/frdm_mcxe31b/frdm_mcxe31b.dts:141 */
			};

			/* node '/soc/peripheral@40000000/intm@27c000' defined in zephyr/dts/arm/nxp/nxp_mcxe31x_common.dtsi:299 */
			intm: intm@27c000 {
				compatible = "nxp,intm"; /* in zephyr/dts/arm/nxp/nxp_mcxe31x_common.dtsi:300 */
				reg = < 0x27c000 0x64 >; /* in zephyr/dts/arm/nxp/nxp_mcxe31x_common.dtsi:301 */
				status = "disabled";     /* in zephyr/dts/arm/nxp/nxp_mcxe31x_common.dtsi:302 */
			};

			/* node '/soc/peripheral@40000000/jdc@394000' defined in zephyr/dts/arm/nxp/nxp_mcxe31x_common.dtsi:305 */
			jdc: jdc@394000 {
				compatible = "nxp,jdc";  /* in zephyr/dts/arm/nxp/nxp_mcxe31x_common.dtsi:306 */
				reg = < 0x394000 0x2c >; /* in zephyr/dts/arm/nxp/nxp_mcxe31x_common.dtsi:307 */
				status = "disabled";     /* in zephyr/dts/arm/nxp/nxp_mcxe31x_common.dtsi:308 */
			};

			/* node '/soc/peripheral@40000000/lcu@98000' defined in zephyr/dts/arm/nxp/nxp_mcxe31x_common.dtsi:311 */
			lcu_0: lcu@98000 {
				compatible = "nxp,lcu";    /* in zephyr/dts/arm/nxp/nxp_mcxe31x_common.dtsi:312 */
				reg = < 0x98000 0x2c8 >;   /* in zephyr/dts/arm/nxp/nxp_mcxe31x_common.dtsi:313 */
				interrupts = < 0x5c 0x0 >; /* in zephyr/dts/arm/nxp/nxp_mcxe31x_common.dtsi:314 */
				status = "disabled";       /* in zephyr/dts/arm/nxp/nxp_mcxe31x_common.dtsi:315 */
			};

			/* node '/soc/peripheral@40000000/lcu@9c000' defined in zephyr/dts/arm/nxp/nxp_mcxe31x_common.dtsi:318 */
			lcu_1: lcu@9c000 {
				compatible = "nxp,lcu";    /* in zephyr/dts/arm/nxp/nxp_mcxe31x_common.dtsi:319 */
				reg = < 0x9c000 0x2c8 >;   /* in zephyr/dts/arm/nxp/nxp_mcxe31x_common.dtsi:320 */
				interrupts = < 0x5d 0x0 >; /* in zephyr/dts/arm/nxp/nxp_mcxe31x_common.dtsi:321 */
				status = "disabled";       /* in zephyr/dts/arm/nxp/nxp_mcxe31x_common.dtsi:322 */
			};

			/* node '/soc/peripheral@40000000/lpcmp@370000' defined in zephyr/dts/arm/nxp/nxp_mcxe31x_common.dtsi:325 */
			lpcmp_0: lpcmp@370000 {
				compatible = "nxp,lpcmp";  /* in zephyr/dts/arm/nxp/nxp_mcxe31x_common.dtsi:326 */
				reg = < 0x370000 0x50 >;   /* in zephyr/dts/arm/nxp/nxp_mcxe31x_common.dtsi:327 */
				interrupts = < 0xb7 0x0 >; /* in zephyr/dts/arm/nxp/nxp_mcxe31x_common.dtsi:328 */
				status = "disabled";       /* in zephyr/dts/arm/nxp/nxp_mcxe31x_common.dtsi:329 */
			};

			/* node '/soc/peripheral@40000000/lpcmp@374000' defined in zephyr/dts/arm/nxp/nxp_mcxe31x_common.dtsi:332 */
			lpcmp_1: lpcmp@374000 {
				compatible = "nxp,lpcmp";  /* in zephyr/dts/arm/nxp/nxp_mcxe31x_common.dtsi:333 */
				reg = < 0x374000 0x50 >;   /* in zephyr/dts/arm/nxp/nxp_mcxe31x_common.dtsi:334 */
				interrupts = < 0xb8 0x0 >; /* in zephyr/dts/arm/nxp/nxp_mcxe31x_common.dtsi:335 */
				status = "disabled";       /* in zephyr/dts/arm/nxp/nxp_mcxe31x_common.dtsi:336 */
			};

			/* node '/soc/peripheral@40000000/lpcmp@4e8000' defined in zephyr/dts/arm/nxp/nxp_mcxe31x_common.dtsi:339 */
			lpcmp_2: lpcmp@4e8000 {
				compatible = "nxp,lpcmp";  /* in zephyr/dts/arm/nxp/nxp_mcxe31x_common.dtsi:340 */
				reg = < 0x4e8000 0x50 >;   /* in zephyr/dts/arm/nxp/nxp_mcxe31x_common.dtsi:341 */
				interrupts = < 0xb9 0x0 >; /* in zephyr/dts/arm/nxp/nxp_mcxe31x_common.dtsi:342 */
				status = "disabled";       /* in zephyr/dts/arm/nxp/nxp_mcxe31x_common.dtsi:343 */
			};

			/* node '/soc/peripheral@40000000/lpi2c@350000' defined in zephyr/dts/arm/nxp/nxp_mcxe31x_common.dtsi:346 */
			lpi2c_0: lpi2c@350000 {
				compatible = "nxp,lpi2c";    /* in zephyr/dts/arm/nxp/nxp_mcxe31x_common.dtsi:347 */
				reg = < 0x350000 0x190 >;    /* in zephyr/dts/arm/nxp/nxp_mcxe31x_common.dtsi:348 */
				interrupts = < 0xa1 0x0 >;   /* in zephyr/dts/arm/nxp/nxp_mcxe31x_common.dtsi:349 */
				clocks = < &mc_cgm 0x2600 >; /* in zephyr/dts/arm/nxp/nxp_mcxe31x_common.dtsi:350 */
				#address-cells = < 0x1 >;    /* in zephyr/dts/arm/nxp/nxp_mcxe31x_common.dtsi:351 */
				#size-cells = < 0x0 >;       /* in zephyr/dts/arm/nxp/nxp_mcxe31x_common.dtsi:352 */
				status = "disabled";         /* in zephyr/dts/arm/nxp/nxp_mcxe31x_common.dtsi:353 */
			};

			/* node '/soc/peripheral@40000000/lpi2c@354000' defined in zephyr/dts/arm/nxp/nxp_mcxe31x_common.dtsi:356 */
			lpi2c_1: lpi2c@354000 {
				compatible = "nxp,lpi2c";    /* in zephyr/dts/arm/nxp/nxp_mcxe31x_common.dtsi:357 */
				reg = < 0x354000 0x190 >;    /* in zephyr/dts/arm/nxp/nxp_mcxe31x_common.dtsi:358 */
				interrupts = < 0xa2 0x0 >;   /* in zephyr/dts/arm/nxp/nxp_mcxe31x_common.dtsi:359 */
				clocks = < &mc_cgm 0x2601 >; /* in zephyr/dts/arm/nxp/nxp_mcxe31x_common.dtsi:360 */
				#address-cells = < 0x1 >;    /* in zephyr/dts/arm/nxp/nxp_mcxe31x_common.dtsi:361 */
				#size-cells = < 0x0 >;       /* in zephyr/dts/arm/nxp/nxp_mcxe31x_common.dtsi:362 */
				status = "disabled";         /* in zephyr/dts/arm/nxp/nxp_mcxe31x_common.dtsi:363 */
			};

			/* node '/soc/peripheral@40000000/lpspi@358000' defined in zephyr/dts/arm/nxp/nxp_mcxe31x_common.dtsi:366 */
			lpspi_0: lpspi@358000 {
				compatible = "nxp,lpspi";    /* in zephyr/dts/arm/nxp/nxp_mcxe31x_common.dtsi:367 */
				reg = < 0x358000 0x81c >;    /* in zephyr/dts/arm/nxp/nxp_mcxe31x_common.dtsi:368 */
				interrupts = < 0xa5 0x0 >;   /* in zephyr/dts/arm/nxp/nxp_mcxe31x_common.dtsi:369 */
				clocks = < &mc_cgm 0x2700 >; /* in zephyr/dts/arm/nxp/nxp_mcxe31x_common.dtsi:370 */
				rx-fifo-size = < 0x4 >;      /* in zephyr/dts/arm/nxp/nxp_mcxe31x_common.dtsi:371 */
				tx-fifo-size = < 0x4 >;      /* in zephyr/dts/arm/nxp/nxp_mcxe31x_common.dtsi:372 */
				#address-cells = < 0x1 >;    /* in zephyr/dts/arm/nxp/nxp_mcxe31x_common.dtsi:373 */
				#size-cells = < 0x0 >;       /* in zephyr/dts/arm/nxp/nxp_mcxe31x_common.dtsi:374 */
				status = "disabled";         /* in zephyr/dts/arm/nxp/nxp_mcxe31x_common.dtsi:375 */
			};

			/* node '/soc/peripheral@40000000/lpspi@35c000' defined in zephyr/dts/arm/nxp/nxp_mcxe31x_common.dtsi:378 */
			lpspi_1: lpspi@35c000 {
				compatible = "nxp,lpspi";    /* in zephyr/dts/arm/nxp/nxp_mcxe31x_common.dtsi:379 */
				reg = < 0x35c000 0x81c >;    /* in zephyr/dts/arm/nxp/nxp_mcxe31x_common.dtsi:380 */
				interrupts = < 0xa6 0x0 >;   /* in zephyr/dts/arm/nxp/nxp_mcxe31x_common.dtsi:381 */
				clocks = < &mc_cgm 0x2701 >; /* in zephyr/dts/arm/nxp/nxp_mcxe31x_common.dtsi:382 */
				rx-fifo-size = < 0x4 >;      /* in zephyr/dts/arm/nxp/nxp_mcxe31x_common.dtsi:383 */
				tx-fifo-size = < 0x4 >;      /* in zephyr/dts/arm/nxp/nxp_mcxe31x_common.dtsi:384 */
				#address-cells = < 0x1 >;    /* in zephyr/dts/arm/nxp/nxp_mcxe31x_common.dtsi:385 */
				#size-cells = < 0x0 >;       /* in zephyr/dts/arm/nxp/nxp_mcxe31x_common.dtsi:386 */
				status = "disabled";         /* in zephyr/dts/arm/nxp/nxp_mcxe31x_common.dtsi:387 */
			};

			/* node '/soc/peripheral@40000000/lpspi@360000' defined in zephyr/dts/arm/nxp/nxp_mcxe31x_common.dtsi:390 */
			lpspi_2: lpspi@360000 {
				compatible = "nxp,lpspi";    /* in zephyr/dts/arm/nxp/nxp_mcxe31x_common.dtsi:391 */
				reg = < 0x360000 0x81c >;    /* in zephyr/dts/arm/nxp/nxp_mcxe31x_common.dtsi:392 */
				interrupts = < 0xa7 0x0 >;   /* in zephyr/dts/arm/nxp/nxp_mcxe31x_common.dtsi:393 */
				clocks = < &mc_cgm 0x2702 >; /* in zephyr/dts/arm/nxp/nxp_mcxe31x_common.dtsi:394 */
				rx-fifo-size = < 0x4 >;      /* in zephyr/dts/arm/nxp/nxp_mcxe31x_common.dtsi:395 */
				tx-fifo-size = < 0x4 >;      /* in zephyr/dts/arm/nxp/nxp_mcxe31x_common.dtsi:396 */
				#address-cells = < 0x1 >;    /* in zephyr/dts/arm/nxp/nxp_mcxe31x_common.dtsi:397 */
				#size-cells = < 0x0 >;       /* in zephyr/dts/arm/nxp/nxp_mcxe31x_common.dtsi:398 */
				status = "disabled";         /* in zephyr/dts/arm/nxp/nxp_mcxe31x_common.dtsi:399 */
			};

			/* node '/soc/peripheral@40000000/lpspi@364000' defined in zephyr/dts/arm/nxp/nxp_mcxe31x_common.dtsi:402 */
			lpspi_3: lpspi@364000 {
				compatible = "nxp,lpspi";    /* in zephyr/dts/arm/nxp/nxp_mcxe31x_common.dtsi:403 */
				reg = < 0x364000 0x81c >;    /* in zephyr/dts/arm/nxp/nxp_mcxe31x_common.dtsi:404 */
				interrupts = < 0xa8 0x0 >;   /* in zephyr/dts/arm/nxp/nxp_mcxe31x_common.dtsi:405 */
				clocks = < &mc_cgm 0x2703 >; /* in zephyr/dts/arm/nxp/nxp_mcxe31x_common.dtsi:406 */
				rx-fifo-size = < 0x4 >;      /* in zephyr/dts/arm/nxp/nxp_mcxe31x_common.dtsi:407 */
				tx-fifo-size = < 0x4 >;      /* in zephyr/dts/arm/nxp/nxp_mcxe31x_common.dtsi:408 */
				#address-cells = < 0x1 >;    /* in zephyr/dts/arm/nxp/nxp_mcxe31x_common.dtsi:409 */
				#size-cells = < 0x0 >;       /* in zephyr/dts/arm/nxp/nxp_mcxe31x_common.dtsi:410 */
				status = "disabled";         /* in zephyr/dts/arm/nxp/nxp_mcxe31x_common.dtsi:411 */
			};

			/* node '/soc/peripheral@40000000/lpspi@4bc000' defined in zephyr/dts/arm/nxp/nxp_mcxe31x_common.dtsi:414 */
			lpspi_4: lpspi@4bc000 {
				compatible = "nxp,lpspi";    /* in zephyr/dts/arm/nxp/nxp_mcxe31x_common.dtsi:415 */
				reg = < 0x4bc000 0x81c >;    /* in zephyr/dts/arm/nxp/nxp_mcxe31x_common.dtsi:416 */
				interrupts = < 0xa9 0x0 >;   /* in zephyr/dts/arm/nxp/nxp_mcxe31x_common.dtsi:417 */
				clocks = < &mc_cgm 0x2704 >; /* in zephyr/dts/arm/nxp/nxp_mcxe31x_common.dtsi:418 */
				rx-fifo-size = < 0x4 >;      /* in zephyr/dts/arm/nxp/nxp_mcxe31x_common.dtsi:419 */
				tx-fifo-size = < 0x4 >;      /* in zephyr/dts/arm/nxp/nxp_mcxe31x_common.dtsi:420 */
				#address-cells = < 0x1 >;    /* in zephyr/dts/arm/nxp/nxp_mcxe31x_common.dtsi:421 */
				#size-cells = < 0x0 >;       /* in zephyr/dts/arm/nxp/nxp_mcxe31x_common.dtsi:422 */
				status = "disabled";         /* in zephyr/dts/arm/nxp/nxp_mcxe31x_common.dtsi:423 */
			};

			/* node '/soc/peripheral@40000000/lpspi@4c0000' defined in zephyr/dts/arm/nxp/nxp_mcxe31x_common.dtsi:426 */
			lpspi_5: lpspi@4c0000 {
				compatible = "nxp,lpspi";    /* in zephyr/dts/arm/nxp/nxp_mcxe31x_common.dtsi:427 */
				reg = < 0x4c0000 0x81c >;    /* in zephyr/dts/arm/nxp/nxp_mcxe31x_common.dtsi:428 */
				interrupts = < 0xaa 0x0 >;   /* in zephyr/dts/arm/nxp/nxp_mcxe31x_common.dtsi:429 */
				clocks = < &mc_cgm 0x2705 >; /* in zephyr/dts/arm/nxp/nxp_mcxe31x_common.dtsi:430 */
				rx-fifo-size = < 0x4 >;      /* in zephyr/dts/arm/nxp/nxp_mcxe31x_common.dtsi:431 */
				tx-fifo-size = < 0x4 >;      /* in zephyr/dts/arm/nxp/nxp_mcxe31x_common.dtsi:432 */
				#address-cells = < 0x1 >;    /* in zephyr/dts/arm/nxp/nxp_mcxe31x_common.dtsi:433 */
				#size-cells = < 0x0 >;       /* in zephyr/dts/arm/nxp/nxp_mcxe31x_common.dtsi:434 */
				status = "disabled";         /* in zephyr/dts/arm/nxp/nxp_mcxe31x_common.dtsi:435 */
			};

			/* node '/soc/peripheral@40000000/lpuart@328000' defined in zephyr/dts/arm/nxp/nxp_mcxe31x_common.dtsi:438 */
			lpuart_0: lpuart@328000 {
				compatible = "nxp,lpuart";   /* in zephyr/dts/arm/nxp/nxp_mcxe31x_common.dtsi:439 */
				reg = < 0x328000 0x50 >;     /* in zephyr/dts/arm/nxp/nxp_mcxe31x_common.dtsi:440 */
				interrupts = < 0x8d 0x0 >;   /* in zephyr/dts/arm/nxp/nxp_mcxe31x_common.dtsi:441 */
				clocks = < &mc_cgm 0x2800 >; /* in zephyr/dts/arm/nxp/nxp_mcxe31x_common.dtsi:442 */
				status = "disabled";         /* in zephyr/dts/arm/nxp/nxp_mcxe31x_common.dtsi:443 */
			};

			/* node '/soc/peripheral@40000000/lpuart@32c000' defined in zephyr/dts/arm/nxp/nxp_mcxe31x_common.dtsi:446 */
			lpuart_1: lpuart@32c000 {
				compatible = "nxp,lpuart";   /* in zephyr/dts/arm/nxp/nxp_mcxe31x_common.dtsi:447 */
				reg = < 0x32c000 0x50 >;     /* in zephyr/dts/arm/nxp/nxp_mcxe31x_common.dtsi:448 */
				interrupts = < 0x8e 0x0 >;   /* in zephyr/dts/arm/nxp/nxp_mcxe31x_common.dtsi:449 */
				clocks = < &mc_cgm 0x2801 >; /* in zephyr/dts/arm/nxp/nxp_mcxe31x_common.dtsi:450 */
				status = "disabled";         /* in zephyr/dts/arm/nxp/nxp_mcxe31x_common.dtsi:451 */
			};

			/* node '/soc/peripheral@40000000/lpuart@330000' defined in zephyr/dts/arm/nxp/nxp_mcxe31x_common.dtsi:454 */
			lpuart_2: lpuart@330000 {
				compatible = "nxp,lpuart";   /* in zephyr/dts/arm/nxp/nxp_mcxe31x_common.dtsi:455 */
				reg = < 0x330000 0x50 >;     /* in zephyr/dts/arm/nxp/nxp_mcxe31x_common.dtsi:456 */
				interrupts = < 0x8f 0x0 >;   /* in zephyr/dts/arm/nxp/nxp_mcxe31x_common.dtsi:457 */
				clocks = < &mc_cgm 0x2802 >; /* in zephyr/dts/arm/nxp/nxp_mcxe31x_common.dtsi:458 */
				status = "disabled";         /* in zephyr/dts/arm/nxp/nxp_mcxe31x_common.dtsi:459 */
			};

			/* node '/soc/peripheral@40000000/lpuart@334000' defined in zephyr/dts/arm/nxp/nxp_mcxe31x_common.dtsi:462 */
			lpuart_3: lpuart@334000 {
				compatible = "nxp,lpuart";   /* in zephyr/dts/arm/nxp/nxp_mcxe31x_common.dtsi:463 */
				reg = < 0x334000 0x50 >;     /* in zephyr/dts/arm/nxp/nxp_mcxe31x_common.dtsi:464 */
				interrupts = < 0x90 0x0 >;   /* in zephyr/dts/arm/nxp/nxp_mcxe31x_common.dtsi:465 */
				clocks = < &mc_cgm 0x2803 >; /* in zephyr/dts/arm/nxp/nxp_mcxe31x_common.dtsi:466 */
				status = "disabled";         /* in zephyr/dts/arm/nxp/nxp_mcxe31x_common.dtsi:467 */
			};

			/* node '/soc/peripheral@40000000/lpuart@338000' defined in zephyr/dts/arm/nxp/nxp_mcxe31x_common.dtsi:470 */
			lpuart_4: lpuart@338000 {
				compatible = "nxp,lpuart";   /* in zephyr/dts/arm/nxp/nxp_mcxe31x_common.dtsi:471 */
				reg = < 0x338000 0x50 >;     /* in zephyr/dts/arm/nxp/nxp_mcxe31x_common.dtsi:472 */
				interrupts = < 0x91 0x0 >;   /* in zephyr/dts/arm/nxp/nxp_mcxe31x_common.dtsi:473 */
				clocks = < &mc_cgm 0x2804 >; /* in zephyr/dts/arm/nxp/nxp_mcxe31x_common.dtsi:474 */
				status = "disabled";         /* in zephyr/dts/arm/nxp/nxp_mcxe31x_common.dtsi:475 */
			};

			/* node '/soc/peripheral@40000000/lpuart@33c000' defined in zephyr/dts/arm/nxp/nxp_mcxe31x_common.dtsi:478 */
			lpuart_5: lpuart@33c000 {
				compatible = "nxp,lpuart";        /* in zephyr/dts/arm/nxp/nxp_mcxe31x_common.dtsi:479 */
				reg = < 0x33c000 0x50 >;          /* in zephyr/dts/arm/nxp/nxp_mcxe31x_common.dtsi:480 */
				interrupts = < 0x92 0x0 >;        /* in zephyr/dts/arm/nxp/nxp_mcxe31x_common.dtsi:481 */
				clocks = < &mc_cgm 0x2805 >;      /* in zephyr/dts/arm/nxp/nxp_mcxe31x_common.dtsi:482 */
				status = "okay";                  /* in zephyr/boards/nxp/frdm_mcxe31b/frdm_mcxe31b.dts:105 */
				current-speed = < 0x1c200 >;      /* in zephyr/boards/nxp/frdm_mcxe31b/frdm_mcxe31b.dts:106 */
				pinctrl-0 = < &pinmux_lpuart_5 >; /* in zephyr/boards/nxp/frdm_mcxe31b/frdm_mcxe31b.dts:107 */
				pinctrl-names = "default";        /* in zephyr/boards/nxp/frdm_mcxe31b/frdm_mcxe31b.dts:108 */
				dmas = < &edma 0x1 0x2c >,
				       < &edma 0x2 0x2d >;        /* in zephyr/boards/nxp/frdm_mcxe31b/frdm_mcxe31b.dts:109 */
				dma-names = "tx",
				            "rx";                 /* in zephyr/boards/nxp/frdm_mcxe31b/frdm_mcxe31b.dts:110 */
			};

			/* node '/soc/peripheral@40000000/lpuart@340000' defined in zephyr/dts/arm/nxp/nxp_mcxe31x_common.dtsi:486 */
			lpuart_6: lpuart@340000 {
				compatible = "nxp,lpuart";   /* in zephyr/dts/arm/nxp/nxp_mcxe31x_common.dtsi:487 */
				reg = < 0x340000 0x50 >;     /* in zephyr/dts/arm/nxp/nxp_mcxe31x_common.dtsi:488 */
				interrupts = < 0x93 0x0 >;   /* in zephyr/dts/arm/nxp/nxp_mcxe31x_common.dtsi:489 */
				clocks = < &mc_cgm 0x2806 >; /* in zephyr/dts/arm/nxp/nxp_mcxe31x_common.dtsi:490 */
				status = "disabled";         /* in zephyr/dts/arm/nxp/nxp_mcxe31x_common.dtsi:491 */
			};

			/* node '/soc/peripheral@40000000/lpuart@344000' defined in zephyr/dts/arm/nxp/nxp_mcxe31x_common.dtsi:494 */
			lpuart_7: lpuart@344000 {
				compatible = "nxp,lpuart";   /* in zephyr/dts/arm/nxp/nxp_mcxe31x_common.dtsi:495 */
				reg = < 0x344000 0x50 >;     /* in zephyr/dts/arm/nxp/nxp_mcxe31x_common.dtsi:496 */
				interrupts = < 0x94 0x0 >;   /* in zephyr/dts/arm/nxp/nxp_mcxe31x_common.dtsi:497 */
				clocks = < &mc_cgm 0x2807 >; /* in zephyr/dts/arm/nxp/nxp_mcxe31x_common.dtsi:498 */
				status = "disabled";         /* in zephyr/dts/arm/nxp/nxp_mcxe31x_common.dtsi:499 */
			};

			/* node '/soc/peripheral@40000000/lpuart@48c000' defined in zephyr/dts/arm/nxp/nxp_mcxe31x_common.dtsi:502 */
			lpuart_8: lpuart@48c000 {
				compatible = "nxp,lpuart";   /* in zephyr/dts/arm/nxp/nxp_mcxe31x_common.dtsi:503 */
				reg = < 0x48c000 0x50 >;     /* in zephyr/dts/arm/nxp/nxp_mcxe31x_common.dtsi:504 */
				interrupts = < 0x95 0x0 >;   /* in zephyr/dts/arm/nxp/nxp_mcxe31x_common.dtsi:505 */
				clocks = < &mc_cgm 0x2808 >; /* in zephyr/dts/arm/nxp/nxp_mcxe31x_common.dtsi:506 */
				status = "disabled";         /* in zephyr/dts/arm/nxp/nxp_mcxe31x_common.dtsi:507 */
			};

			/* node '/soc/peripheral@40000000/lpuart@490000' defined in zephyr/dts/arm/nxp/nxp_mcxe31x_common.dtsi:510 */
			lpuart_9: lpuart@490000 {
				compatible = "nxp,lpuart";   /* in zephyr/dts/arm/nxp/nxp_mcxe31x_common.dtsi:511 */
				reg = < 0x490000 0x50 >;     /* in zephyr/dts/arm/nxp/nxp_mcxe31x_common.dtsi:512 */
				interrupts = < 0x96 0x0 >;   /* in zephyr/dts/arm/nxp/nxp_mcxe31x_common.dtsi:513 */
				clocks = < &mc_cgm 0x2809 >; /* in zephyr/dts/arm/nxp/nxp_mcxe31x_common.dtsi:514 */
				status = "disabled";         /* in zephyr/dts/arm/nxp/nxp_mcxe31x_common.dtsi:515 */
			};

			/* node '/soc/peripheral@40000000/lpuart@494000' defined in zephyr/dts/arm/nxp/nxp_mcxe31x_common.dtsi:518 */
			lpuart_10: lpuart@494000 {
				compatible = "nxp,lpuart";   /* in zephyr/dts/arm/nxp/nxp_mcxe31x_common.dtsi:519 */
				reg = < 0x494000 0x50 >;     /* in zephyr/dts/arm/nxp/nxp_mcxe31x_common.dtsi:520 */
				interrupts = < 0x97 0x0 >;   /* in zephyr/dts/arm/nxp/nxp_mcxe31x_common.dtsi:521 */
				clocks = < &mc_cgm 0x280a >; /* in zephyr/dts/arm/nxp/nxp_mcxe31x_common.dtsi:522 */
				status = "disabled";         /* in zephyr/dts/arm/nxp/nxp_mcxe31x_common.dtsi:523 */
			};

			/* node '/soc/peripheral@40000000/lpuart@498000' defined in zephyr/dts/arm/nxp/nxp_mcxe31x_common.dtsi:526 */
			lpuart_11: lpuart@498000 {
				compatible = "nxp,lpuart";   /* in zephyr/dts/arm/nxp/nxp_mcxe31x_common.dtsi:527 */
				reg = < 0x498000 0x50 >;     /* in zephyr/dts/arm/nxp/nxp_mcxe31x_common.dtsi:528 */
				interrupts = < 0x98 0x0 >;   /* in zephyr/dts/arm/nxp/nxp_mcxe31x_common.dtsi:529 */
				clocks = < &mc_cgm 0x280b >; /* in zephyr/dts/arm/nxp/nxp_mcxe31x_common.dtsi:530 */
				status = "disabled";         /* in zephyr/dts/arm/nxp/nxp_mcxe31x_common.dtsi:531 */
			};

			/* node '/soc/peripheral@40000000/lpuart@49c000' defined in zephyr/dts/arm/nxp/nxp_mcxe31x_common.dtsi:534 */
			lpuart_12: lpuart@49c000 {
				compatible = "nxp,lpuart";   /* in zephyr/dts/arm/nxp/nxp_mcxe31x_common.dtsi:535 */
				reg = < 0x49c000 0x50 >;     /* in zephyr/dts/arm/nxp/nxp_mcxe31x_common.dtsi:536 */
				interrupts = < 0x99 0x0 >;   /* in zephyr/dts/arm/nxp/nxp_mcxe31x_common.dtsi:537 */
				clocks = < &mc_cgm 0x280c >; /* in zephyr/dts/arm/nxp/nxp_mcxe31x_common.dtsi:538 */
				status = "disabled";         /* in zephyr/dts/arm/nxp/nxp_mcxe31x_common.dtsi:539 */
			};

			/* node '/soc/peripheral@40000000/lpuart@4a0000' defined in zephyr/dts/arm/nxp/nxp_mcxe31x_common.dtsi:542 */
			lpuart_13: lpuart@4a0000 {
				compatible = "nxp,lpuart";   /* in zephyr/dts/arm/nxp/nxp_mcxe31x_common.dtsi:543 */
				reg = < 0x4a0000 0x50 >;     /* in zephyr/dts/arm/nxp/nxp_mcxe31x_common.dtsi:544 */
				interrupts = < 0x9a 0x0 >;   /* in zephyr/dts/arm/nxp/nxp_mcxe31x_common.dtsi:545 */
				clocks = < &mc_cgm 0x280d >; /* in zephyr/dts/arm/nxp/nxp_mcxe31x_common.dtsi:546 */
				status = "disabled";         /* in zephyr/dts/arm/nxp/nxp_mcxe31x_common.dtsi:547 */
			};

			/* node '/soc/peripheral@40000000/lpuart@4a4000' defined in zephyr/dts/arm/nxp/nxp_mcxe31x_common.dtsi:550 */
			lpuart_14: lpuart@4a4000 {
				compatible = "nxp,lpuart";   /* in zephyr/dts/arm/nxp/nxp_mcxe31x_common.dtsi:551 */
				reg = < 0x4a4000 0x50 >;     /* in zephyr/dts/arm/nxp/nxp_mcxe31x_common.dtsi:552 */
				interrupts = < 0x9b 0x0 >;   /* in zephyr/dts/arm/nxp/nxp_mcxe31x_common.dtsi:553 */
				clocks = < &mc_cgm 0x280e >; /* in zephyr/dts/arm/nxp/nxp_mcxe31x_common.dtsi:554 */
				status = "disabled";         /* in zephyr/dts/arm/nxp/nxp_mcxe31x_common.dtsi:555 */
			};

			/* node '/soc/peripheral@40000000/lpuart@4a8000' defined in zephyr/dts/arm/nxp/nxp_mcxe31x_common.dtsi:558 */
			lpuart_15: lpuart@4a8000 {
				compatible = "nxp,lpuart";   /* in zephyr/dts/arm/nxp/nxp_mcxe31x_common.dtsi:559 */
				reg = < 0x4a8000 0x50 >;     /* in zephyr/dts/arm/nxp/nxp_mcxe31x_common.dtsi:560 */
				interrupts = < 0x9c 0x0 >;   /* in zephyr/dts/arm/nxp/nxp_mcxe31x_common.dtsi:561 */
				clocks = < &mc_cgm 0x280f >; /* in zephyr/dts/arm/nxp/nxp_mcxe31x_common.dtsi:562 */
				status = "disabled";         /* in zephyr/dts/arm/nxp/nxp_mcxe31x_common.dtsi:563 */
			};

			/* node '/soc/peripheral@40000000/mc_cgm@2d8000' defined in zephyr/dts/arm/nxp/nxp_mcxe31x_common.dtsi:566 */
			mc_cgm: mc_cgm@2d8000 {
				compatible = "nxp,mc-cgm";    /* in zephyr/dts/arm/nxp/nxp_mcxe31x_common.dtsi:567 */
				reg = < 0x2d8000 0x61c >;     /* in zephyr/dts/arm/nxp/nxp_mcxe31x_common.dtsi:568 */
				#clock-cells = < 0x1 >;       /* in zephyr/dts/arm/nxp/nxp_mcxe31x_common.dtsi:569 */
				status = "okay";              /* in zephyr/boards/nxp/frdm_mcxe31b/frdm_mcxe31b.dts:158 */
				max-ido-change = < 0x32 >;    /* in zephyr/boards/nxp/frdm_mcxe31b/frdm_mcxe31b.dts:159 */
				step-duration = < 0x1 >;      /* in zephyr/boards/nxp/frdm_mcxe31b/frdm_mcxe31b.dts:160 */
				clk-src-freq = < 0x9896800 >; /* in zephyr/boards/nxp/frdm_mcxe31b/frdm_mcxe31b.dts:161 */
				mux-0-dc-0-div = < 0x1 >;     /* in zephyr/boards/nxp/frdm_mcxe31b/frdm_mcxe31b.dts:162 */
				mux-0-dc-1-div = < 0x2 >;     /* in zephyr/boards/nxp/frdm_mcxe31b/frdm_mcxe31b.dts:163 */
				mux-0-dc-2-div = < 0x4 >;     /* in zephyr/boards/nxp/frdm_mcxe31b/frdm_mcxe31b.dts:164 */
				mux-0-dc-3-div = < 0x2 >;     /* in zephyr/boards/nxp/frdm_mcxe31b/frdm_mcxe31b.dts:165 */
				mux-0-dc-4-div = < 0x4 >;     /* in zephyr/boards/nxp/frdm_mcxe31b/frdm_mcxe31b.dts:166 */
				mux-0-dc-5-div = < 0x4 >;     /* in zephyr/boards/nxp/frdm_mcxe31b/frdm_mcxe31b.dts:167 */
				mux-0-dc-6-div = < 0x1 >;     /* in zephyr/boards/nxp/frdm_mcxe31b/frdm_mcxe31b.dts:168 */
				mux-1-dc-0-div = < 0x1 >;     /* in zephyr/boards/nxp/frdm_mcxe31b/frdm_mcxe31b.dts:169 */
				mux-2-dc-0-div = < 0x1 >;     /* in zephyr/boards/nxp/frdm_mcxe31b/frdm_mcxe31b.dts:170 */
				phandle = < 0x2 >;            /* in zephyr/dts/arm/nxp/nxp_mcxe31x_common.dtsi:230 */
			};

			/* node '/soc/peripheral@40000000/mc-me@2dc000' defined in zephyr/dts/arm/nxp/nxp_mcxe31x_common.dtsi:573 */
			mc_me: mc-me@2dc000 {
				compatible = "nxp,mc-me"; /* in zephyr/dts/arm/nxp/nxp_mcxe31x_common.dtsi:574 */
				reg = < 0x2dc000 0x554 >; /* in zephyr/dts/arm/nxp/nxp_mcxe31x_common.dtsi:575 */
				status = "disabled";      /* in zephyr/dts/arm/nxp/nxp_mcxe31x_common.dtsi:576 */
			};

			/* node '/soc/peripheral@40000000/mc-rgm@28c000' defined in zephyr/dts/arm/nxp/nxp_mcxe31x_common.dtsi:579 */
			mc_rgm: mc-rgm@28c000 {
				compatible = "nxp,mc-rgm"; /* in zephyr/dts/arm/nxp/nxp_mcxe31x_common.dtsi:580 */
				reg = < 0x28c000 0x4c >;   /* in zephyr/dts/arm/nxp/nxp_mcxe31x_common.dtsi:581 */
				status = "disabled";       /* in zephyr/dts/arm/nxp/nxp_mcxe31x_common.dtsi:582 */
			};

			/* node '/soc/peripheral@40000000/mcm@e0080000' defined in zephyr/dts/arm/nxp/nxp_mcxe31x_common.dtsi:585 */
			mcm_0: mcm@e0080000 {
				compatible = "nxp,mcm";     /* in zephyr/dts/arm/nxp/nxp_mcxe31x_common.dtsi:586 */
				reg = < 0xe0080000 0x430 >; /* in zephyr/dts/arm/nxp/nxp_mcxe31x_common.dtsi:587 */
				status = "disabled";        /* in zephyr/dts/arm/nxp/nxp_mcxe31x_common.dtsi:588 */
			};

			/* node '/soc/peripheral@40000000/mdm-ap@250600' defined in zephyr/dts/arm/nxp/nxp_mcxe31x_common.dtsi:591 */
			mdm_ap: mdm-ap@250600 {
				compatible = "nxp,mdm-ap"; /* in zephyr/dts/arm/nxp/nxp_mcxe31x_common.dtsi:592 */
				reg = < 0x250600 0x11c >;  /* in zephyr/dts/arm/nxp/nxp_mcxe31x_common.dtsi:593 */
				status = "disabled";       /* in zephyr/dts/arm/nxp/nxp_mcxe31x_common.dtsi:594 */
			};

			/* node '/soc/peripheral@40000000/mscm@260000' defined in zephyr/dts/arm/nxp/nxp_mcxe31x_common.dtsi:597 */
			mscm: mscm@260000 {
				compatible = "nxp,mscm";  /* in zephyr/dts/arm/nxp/nxp_mcxe31x_common.dtsi:598 */
				reg = < 0x260000 0xa6e >; /* in zephyr/dts/arm/nxp/nxp_mcxe31x_common.dtsi:599 */
				status = "disabled";      /* in zephyr/dts/arm/nxp/nxp_mcxe31x_common.dtsi:600 */
			};

			/* node '/soc/peripheral@40000000/mu@38c000' defined in zephyr/dts/arm/nxp/nxp_mcxe31x_common.dtsi:603 */
			mu0_b: mu@38c000 {
				compatible = "nxp,mu";    /* in zephyr/dts/arm/nxp/nxp_mcxe31x_common.dtsi:604 */
				reg = < 0x38c000 0x2ac >; /* in zephyr/dts/arm/nxp/nxp_mcxe31x_common.dtsi:605 */
				status = "disabled";      /* in zephyr/dts/arm/nxp/nxp_mcxe31x_common.dtsi:606 */
			};

			/* node '/soc/peripheral@40000000/mu@4ec000' defined in zephyr/dts/arm/nxp/nxp_mcxe31x_common.dtsi:609 */
			mu1_b: mu@4ec000 {
				compatible = "nxp,mu";    /* in zephyr/dts/arm/nxp/nxp_mcxe31x_common.dtsi:610 */
				reg = < 0x4ec000 0x2ac >; /* in zephyr/dts/arm/nxp/nxp_mcxe31x_common.dtsi:611 */
			};

			/* node '/soc/peripheral@40000000/pflash@268000' defined in zephyr/dts/arm/nxp/nxp_mcxe31x_common.dtsi:614 */
			pflash: pflash@268000 {
				compatible = "nxp,pflash"; /* in zephyr/dts/arm/nxp/nxp_mcxe31x_common.dtsi:615 */
				reg = < 0x268000 0x4dc >;  /* in zephyr/dts/arm/nxp/nxp_mcxe31x_common.dtsi:616 */
				status = "disabled";       /* in zephyr/dts/arm/nxp/nxp_mcxe31x_common.dtsi:617 */
			};

			/* node '/soc/peripheral@40000000/pit@b0000' defined in zephyr/dts/arm/nxp/nxp_mcxe31x_common.dtsi:620 */
			pit_0: pit@b0000 {
				compatible = "nxp,pit";          /* in zephyr/dts/arm/nxp/nxp_mcxe31x_common.dtsi:621 */
				reg = < 0xb0000 0x15c >;         /* in zephyr/dts/arm/nxp/nxp_mcxe31x_common.dtsi:622 */
				interrupts = < 0x60 0x0 >;       /* in zephyr/dts/arm/nxp/nxp_mcxe31x_common.dtsi:623 */
				clocks = < &mc_cgm 0x2900 >;     /* in zephyr/dts/arm/nxp/nxp_mcxe31x_common.dtsi:624 */
				max-load-value = < 0xffffffff >; /* in zephyr/dts/arm/nxp/nxp_mcxe31x_common.dtsi:625 */
				status = "disabled";             /* in zephyr/dts/arm/nxp/nxp_mcxe31x_common.dtsi:626 */
			};

			/* node '/soc/peripheral@40000000/pit@b4000' defined in zephyr/dts/arm/nxp/nxp_mcxe31x_common.dtsi:629 */
			pit_1: pit@b4000 {
				compatible = "nxp,pit";          /* in zephyr/dts/arm/nxp/nxp_mcxe31x_common.dtsi:630 */
				reg = < 0xb4000 0x15c >;         /* in zephyr/dts/arm/nxp/nxp_mcxe31x_common.dtsi:631 */
				interrupts = < 0x61 0x0 >;       /* in zephyr/dts/arm/nxp/nxp_mcxe31x_common.dtsi:632 */
				clocks = < &mc_cgm 0x2901 >;     /* in zephyr/dts/arm/nxp/nxp_mcxe31x_common.dtsi:633 */
				max-load-value = < 0xffffffff >; /* in zephyr/dts/arm/nxp/nxp_mcxe31x_common.dtsi:634 */
				status = "disabled";             /* in zephyr/dts/arm/nxp/nxp_mcxe31x_common.dtsi:635 */
			};

			/* node '/soc/peripheral@40000000/pit@2fc000' defined in zephyr/dts/arm/nxp/nxp_mcxe31x_common.dtsi:638 */
			pit_2: pit@2fc000 {
				compatible = "nxp,pit";          /* in zephyr/dts/arm/nxp/nxp_mcxe31x_common.dtsi:639 */
				reg = < 0x2fc000 0x15c >;        /* in zephyr/dts/arm/nxp/nxp_mcxe31x_common.dtsi:640 */
				interrupts = < 0x62 0x0 >;       /* in zephyr/dts/arm/nxp/nxp_mcxe31x_common.dtsi:641 */
				clocks = < &mc_cgm 0x2902 >;     /* in zephyr/dts/arm/nxp/nxp_mcxe31x_common.dtsi:642 */
				max-load-value = < 0xffffffff >; /* in zephyr/dts/arm/nxp/nxp_mcxe31x_common.dtsi:643 */
				status = "disabled";             /* in zephyr/dts/arm/nxp/nxp_mcxe31x_common.dtsi:644 */
			};

			/* node '/soc/peripheral@40000000/plldig@402e0000' defined in zephyr/dts/arm/nxp/nxp_mcxe31x_common.dtsi:647 */
			pll: plldig@402e0000 {
				compatible = "nxp,plldig"; /* in zephyr/dts/arm/nxp/nxp_mcxe31x_common.dtsi:648 */
				reg = < 0x402e0000 0xa4 >; /* in zephyr/dts/arm/nxp/nxp_mcxe31x_common.dtsi:649 */
				status = "okay";           /* in zephyr/boards/nxp/frdm_mcxe31b/frdm_mcxe31b.dts:145 */
				workmode = "Integer";      /* in zephyr/boards/nxp/frdm_mcxe31b/frdm_mcxe31b.dts:146 */
				prediv = < 0x2 >;          /* in zephyr/boards/nxp/frdm_mcxe31b/frdm_mcxe31b.dts:147 */
				postdiv = < 0x2 >;         /* in zephyr/boards/nxp/frdm_mcxe31b/frdm_mcxe31b.dts:148 */
				multiplier = < 0x78 >;     /* in zephyr/boards/nxp/frdm_mcxe31b/frdm_mcxe31b.dts:149 */
				fracloopdiv = < 0x0 >;     /* in zephyr/boards/nxp/frdm_mcxe31b/frdm_mcxe31b.dts:150 */
				stepsize = < 0x0 >;        /* in zephyr/boards/nxp/frdm_mcxe31b/frdm_mcxe31b.dts:151 */
				stepnum = < 0x0 >;         /* in zephyr/boards/nxp/frdm_mcxe31b/frdm_mcxe31b.dts:152 */
				accuracy = "Accuracy9";    /* in zephyr/boards/nxp/frdm_mcxe31b/frdm_mcxe31b.dts:153 */
				outdiv = < 0x3 0x3 >;      /* in zephyr/boards/nxp/frdm_mcxe31b/frdm_mcxe31b.dts:154 */
			};

			/* node '/soc/peripheral@40000000/pmc@2e8000' defined in zephyr/dts/arm/nxp/nxp_mcxe31x_common.dtsi:653 */
			pmc: pmc@2e8000 {
				compatible = "nxp,pmc";    /* in zephyr/dts/arm/nxp/nxp_mcxe31x_common.dtsi:654 */
				reg = < 0x2e8000 0x2c >;   /* in zephyr/dts/arm/nxp/nxp_mcxe31x_common.dtsi:655 */
				interrupts = < 0x34 0x0 >; /* in zephyr/dts/arm/nxp/nxp_mcxe31x_common.dtsi:656 */
				status = "disabled";       /* in zephyr/dts/arm/nxp/nxp_mcxe31x_common.dtsi:657 */
			};

			/* node '/soc/peripheral@40000000/pramc@264000' defined in zephyr/dts/arm/nxp/nxp_mcxe31x_common.dtsi:660 */
			pramc_0: pramc@264000 {
				compatible = "nxp,pramc"; /* in zephyr/dts/arm/nxp/nxp_mcxe31x_common.dtsi:661 */
				reg = < 0x264000 0x20 >;  /* in zephyr/dts/arm/nxp/nxp_mcxe31x_common.dtsi:662 */
				status = "disabled";      /* in zephyr/dts/arm/nxp/nxp_mcxe31x_common.dtsi:663 */
			};

			/* node '/soc/peripheral@40000000/pramc@464000' defined in zephyr/dts/arm/nxp/nxp_mcxe31x_common.dtsi:666 */
			pramc_1: pramc@464000 {
				compatible = "nxp,pramc"; /* in zephyr/dts/arm/nxp/nxp_mcxe31x_common.dtsi:667 */
				reg = < 0x464000 0x20 >;  /* in zephyr/dts/arm/nxp/nxp_mcxe31x_common.dtsi:668 */
				status = "disabled";      /* in zephyr/dts/arm/nxp/nxp_mcxe31x_common.dtsi:669 */
			};

			/* node '/soc/peripheral@40000000/qspi@4cc000' defined in zephyr/dts/arm/nxp/nxp_mcxe31x_common.dtsi:672 */
			quadspi: qspi@4cc000 {
				compatible = "nxp,qspi";   /* in zephyr/dts/arm/nxp/nxp_mcxe31x_common.dtsi:673 */
				reg = < 0x4cc000 0x37c >;  /* in zephyr/dts/arm/nxp/nxp_mcxe31x_common.dtsi:674 */
				interrupts = < 0xad 0x0 >; /* in zephyr/dts/arm/nxp/nxp_mcxe31x_common.dtsi:675 */
				status = "disabled";       /* in zephyr/dts/arm/nxp/nxp_mcxe31x_common.dtsi:676 */
			};

			/* node '/soc/peripheral@40000000/quadspi_ardb@68000000' defined in zephyr/dts/arm/nxp/nxp_mcxe31x_common.dtsi:679 */
			quadspi_ardb: quadspi_ardb@68000000 {
				compatible = "nxp,quadspi_ardb"; /* in zephyr/dts/arm/nxp/nxp_mcxe31x_common.dtsi:680 */
				reg = < 0x68000000 0x21c >;      /* in zephyr/dts/arm/nxp/nxp_mcxe31x_common.dtsi:681 */
				status = "disabled";             /* in zephyr/dts/arm/nxp/nxp_mcxe31x_common.dtsi:682 */
			};

			/* node '/soc/peripheral@40000000/rtc@288000' defined in zephyr/dts/arm/nxp/nxp_mcxe31x_common.dtsi:685 */
			rtc: rtc@288000 {
				compatible = "nxp,rtc-jdp";   /* in zephyr/dts/arm/nxp/nxp_mcxe31x_common.dtsi:686 */
				reg = < 0x288000 0x34 >;      /* in zephyr/dts/arm/nxp/nxp_mcxe31x_common.dtsi:687 */
				interrupts = < 0x66 0x0 >;    /* in zephyr/dts/arm/nxp/nxp_mcxe31x_common.dtsi:688 */
				clock-frequency = < 0x7d00 >; /* in zephyr/dts/arm/nxp/nxp_mcxe31x_common.dtsi:689 */
				clock-source = < 0x1 >;       /* in zephyr/dts/arm/nxp/nxp_mcxe31x_common.dtsi:690 */
				prescaler = < 0x4000 >;       /* in zephyr/dts/arm/nxp/nxp_mcxe31x_common.dtsi:691 */
				status = "okay";              /* in zephyr/boards/nxp/frdm_mcxe31b/frdm_mcxe31b.dts:179 */

				/* node '/soc/peripheral@40000000/rtc@288000/counter-rtc' defined in zephyr/dts/arm/nxp/nxp_mcxe31x_common.dtsi:694 */
				counter_rtc: counter-rtc {
					compatible = "zephyr,rtc-counter"; /* in zephyr/dts/arm/nxp/nxp_mcxe31x_common.dtsi:695 */
					alarms-count = < 0x2 >;            /* in zephyr/dts/arm/nxp/nxp_mcxe31x_common.dtsi:696 */
					status = "okay";                   /* in zephyr/boards/nxp/frdm_mcxe31b/frdm_mcxe31b.dts:183 */
				};
			};

			/* node '/soc/peripheral@40000000/sai@36c000' defined in zephyr/dts/arm/nxp/nxp_mcxe31x_common.dtsi:701 */
			sai_0: sai@36c000 {
				compatible = "nxp,sai";    /* in zephyr/dts/arm/nxp/nxp_mcxe31x_common.dtsi:702 */
				reg = < 0x36c000 0x100 >;  /* in zephyr/dts/arm/nxp/nxp_mcxe31x_common.dtsi:703 */
				interrupts = < 0xae 0x0 >; /* in zephyr/dts/arm/nxp/nxp_mcxe31x_common.dtsi:704 */
				status = "disabled";       /* in zephyr/dts/arm/nxp/nxp_mcxe31x_common.dtsi:705 */
			};

			/* node '/soc/peripheral@40000000/sai@4dc000' defined in zephyr/dts/arm/nxp/nxp_mcxe31x_common.dtsi:708 */
			sai_1: sai@4dc000 {
				compatible = "nxp,sai";    /* in zephyr/dts/arm/nxp/nxp_mcxe31x_common.dtsi:709 */
				reg = < 0x4dc000 0x100 >;  /* in zephyr/dts/arm/nxp/nxp_mcxe31x_common.dtsi:710 */
				interrupts = < 0xaf 0x0 >; /* in zephyr/dts/arm/nxp/nxp_mcxe31x_common.dtsi:711 */
				status = "disabled";       /* in zephyr/dts/arm/nxp/nxp_mcxe31x_common.dtsi:712 */
			};

			/* node '/soc/peripheral@40000000/sda-ap@254700' defined in zephyr/dts/arm/nxp/nxp_mcxe31x_common.dtsi:715 */
			sda_ap: sda-ap@254700 {
				compatible = "nxp,sda-ap"; /* in zephyr/dts/arm/nxp/nxp_mcxe31x_common.dtsi:716 */
				reg = < 0x254700 0x11c >;  /* in zephyr/dts/arm/nxp/nxp_mcxe31x_common.dtsi:717 */
				status = "disabled";       /* in zephyr/dts/arm/nxp/nxp_mcxe31x_common.dtsi:718 */
			};

			/* node '/soc/peripheral@40000000/selftest-gpr@3b0000' defined in zephyr/dts/arm/nxp/nxp_mcxe31x_common.dtsi:721 */
			selftest: selftest-gpr@3b0000 {
				compatible = "nxp,selftest-gpr"; /* in zephyr/dts/arm/nxp/nxp_mcxe31x_common.dtsi:722 */
				reg = < 0x3b0000 0x34 >;         /* in zephyr/dts/arm/nxp/nxp_mcxe31x_common.dtsi:723 */
				status = "disabled";             /* in zephyr/dts/arm/nxp/nxp_mcxe31x_common.dtsi:724 */
			};

			/* node '/soc/peripheral@40000000/sema42@460000' defined in zephyr/dts/arm/nxp/nxp_mcxe31x_common.dtsi:727 */
			sema42: sema42@460000 {
				compatible = "nxp,sema42"; /* in zephyr/dts/arm/nxp/nxp_mcxe31x_common.dtsi:728 */
				reg = < 0x460000 0x52 >;   /* in zephyr/dts/arm/nxp/nxp_mcxe31x_common.dtsi:729 */
				status = "disabled";       /* in zephyr/dts/arm/nxp/nxp_mcxe31x_common.dtsi:730 */
			};

			/* node '/soc/peripheral@40000000/sirc@402c8000' defined in zephyr/dts/arm/nxp/nxp_mcxe31x_common.dtsi:733 */
			sirc: sirc@402c8000 {
				compatible = "nxp,sirc";   /* in zephyr/dts/arm/nxp/nxp_mcxe31x_common.dtsi:734 */
				reg = < 0x402c8000 0x2c >; /* in zephyr/dts/arm/nxp/nxp_mcxe31x_common.dtsi:735 */
				status = "disabled";       /* in zephyr/dts/arm/nxp/nxp_mcxe31x_common.dtsi:736 */
			};

			/* node '/soc/peripheral@40000000/siul2@290000' defined in zephyr/dts/arm/nxp/nxp_mcxe31x_common.dtsi:739 */
			siul2_0: siul2@290000 {
				reg = < 0x290000 0x17d4 >;        /* in zephyr/dts/arm/nxp/nxp_mcxe31x_common.dtsi:740 */
				#address-cells = < 0x1 >;         /* in zephyr/dts/arm/nxp/nxp_mcxe31x_common.dtsi:741 */
				#size-cells = < 0x1 >;            /* in zephyr/dts/arm/nxp/nxp_mcxe31x_common.dtsi:742 */
				ranges = < 0x0 0x290000 0x17d4 >; /* in zephyr/dts/arm/nxp/nxp_mcxe31x_common.dtsi:743 */

				/* node '/soc/peripheral@40000000/siul2@290000/eirq@10' defined in zephyr/dts/arm/nxp/nxp_mcxe31x_common.dtsi:745 */
				eirq0: eirq@10 {
					compatible = "nxp,siul2-eirq";  /* in zephyr/dts/arm/nxp/nxp_mcxe31x_common.dtsi:746 */
					reg = < 0x10 0xb4 >;            /* in zephyr/dts/arm/nxp/nxp_mcxe31x_common.dtsi:747 */
					#address-cells = < 0x0 >;       /* in zephyr/dts/arm/nxp/nxp_mcxe31x_common.dtsi:748 */
					interrupts = < 0x35 0x0 >,
					             < 0x36 0x0 >,
					             < 0x37 0x0 >,
					             < 0x38 0x0 >;      /* in zephyr/dts/arm/nxp/nxp_mcxe31x_common.dtsi:749 */
					interrupt-controller;           /* in zephyr/dts/arm/nxp/nxp_mcxe31x_common.dtsi:750 */
					#interrupt-cells = < 0x2 >;     /* in zephyr/dts/arm/nxp/nxp_mcxe31x_common.dtsi:751 */
					pinctrl-0 = < &eirq0_default >; /* in zephyr/boards/nxp/frdm_mcxe31b/frdm_mcxe31b.dts:126 */
					pinctrl-names = "default";      /* in zephyr/boards/nxp/frdm_mcxe31b/frdm_mcxe31b.dts:127 */
					status = "okay";                /* in zephyr/boards/nxp/frdm_mcxe31b/frdm_mcxe31b.dts:128 */
					phandle = < 0x6 >;              /* in zephyr/dts/arm/nxp/nxp_mcxe31x_common.dtsi:759 */
				};

				/* node '/soc/peripheral@40000000/siul2@290000/gpio@1702' defined in zephyr/dts/arm/nxp/nxp_mcxe31x_common.dtsi:755 */
				gpioa_l: gpio@1702 {
					compatible = "nxp,siul2-gpio";      /* in zephyr/dts/arm/nxp/nxp_mcxe31x_common.dtsi:756 */
					reg = < 0x1702 0x2 >,
					      < 0x240 0x40 >;               /* in zephyr/dts/arm/nxp/nxp_mcxe31x_common.dtsi:757 */
					reg-names = "pgpdo",
					            "mscr";                 /* in zephyr/dts/arm/nxp/nxp_mcxe31x_common.dtsi:758 */
					interrupt-parent = < &eirq0 >;      /* in zephyr/dts/arm/nxp/nxp_mcxe31x_common.dtsi:759 */
					interrupts = < 0x0 0x0 >,
					             < 0x1 0x1 >,
					             < 0x2 0x2 >,
					             < 0x3 0x3 >,
					             < 0x4 0x4 >,
					             < 0x5 0x5 >,
					             < 0x6 0x6 >,
					             < 0x7 0x7 >,
					             < 0x8 0x10 >,
					             < 0x9 0x11 >,
					             < 0xa 0x12 >,
					             < 0xb 0x13 >,
					             < 0xc 0x14 >,
					             < 0xd 0x15 >,
					             < 0xe 0x16 >,
					             < 0xf 0x17 >;          /* in zephyr/dts/arm/nxp/nxp_mcxe31x_common.dtsi:760 */
					nxp,wkpu = < &wkpu >;               /* in zephyr/dts/arm/nxp/nxp_mcxe31x_common.dtsi:764 */
					nxp,wkpu-interrupts = < 0x1 0x9 >,
					                      < 0x2 0x4 >,
					                      < 0x6 0x13 >,
					                      < 0x8 0x1b >,
					                      < 0x9 0x19 >,
					                      < 0xd 0x8 >,
					                      < 0xf 0x18 >; /* in zephyr/dts/arm/nxp/nxp_mcxe31x_common.dtsi:765 */
					gpio-controller;                    /* in zephyr/dts/arm/nxp/nxp_mcxe31x_common.dtsi:767 */
					#gpio-cells = < 0x2 >;              /* in zephyr/dts/arm/nxp/nxp_mcxe31x_common.dtsi:768 */
					ngpios = < 0x10 >;                  /* in zephyr/dts/arm/nxp/nxp_mcxe31x_common.dtsi:769 */
					status = "disabled";                /* in zephyr/dts/arm/nxp/nxp_mcxe31x_common.dtsi:770 */
					phandle = < 0xe >;                  /* in zephyr/boards/nxp/frdm_mcxe31b/frdm_mcxe31b.dts:71 */
				};

				/* node '/soc/peripheral@40000000/siul2@290000/gpio@1700' defined in zephyr/dts/arm/nxp/nxp_mcxe31x_common.dtsi:773 */
				gpioa_h: gpio@1700 {
					compatible = "nxp,siul2-gpio";      /* in zephyr/dts/arm/nxp/nxp_mcxe31x_common.dtsi:774 */
					reg = < 0x1700 0x2 >,
					      < 0x280 0x40 >;               /* in zephyr/dts/arm/nxp/nxp_mcxe31x_common.dtsi:775 */
					reg-names = "pgpdo",
					            "mscr";                 /* in zephyr/dts/arm/nxp/nxp_mcxe31x_common.dtsi:776 */
					interrupt-parent = < &eirq0 >;      /* in zephyr/dts/arm/nxp/nxp_mcxe31x_common.dtsi:777 */
					interrupts = < 0x0 0x4 >,
					             < 0x2 0x0 >,
					             < 0x3 0x1 >,
					             < 0x4 0x2 >,
					             < 0x5 0x3 >,
					             < 0x9 0x5 >,
					             < 0xc 0x6 >,
					             < 0xe 0x7 >;           /* in zephyr/dts/arm/nxp/nxp_mcxe31x_common.dtsi:778 */
					nxp,wkpu = < &wkpu >;               /* in zephyr/dts/arm/nxp/nxp_mcxe31x_common.dtsi:780 */
					nxp,wkpu-interrupts = < 0x0 0x23 >,
					                      < 0x4 0x3f >,
					                      < 0x9 0x26 >,
					                      < 0xa 0x27 >,
					                      < 0xe 0x29 >; /* in zephyr/dts/arm/nxp/nxp_mcxe31x_common.dtsi:781 */
					gpio-controller;                    /* in zephyr/dts/arm/nxp/nxp_mcxe31x_common.dtsi:783 */
					#gpio-cells = < 0x2 >;              /* in zephyr/dts/arm/nxp/nxp_mcxe31x_common.dtsi:784 */
					ngpios = < 0x10 >;                  /* in zephyr/dts/arm/nxp/nxp_mcxe31x_common.dtsi:785 */
					status = "disabled";                /* in zephyr/dts/arm/nxp/nxp_mcxe31x_common.dtsi:786 */
					phandle = < 0xf >;                  /* in zephyr/boards/nxp/frdm_mcxe31b/frdm_mcxe31b.dts:71 */
				};

				/* node '/soc/peripheral@40000000/siul2@290000/gpio@1706' defined in zephyr/dts/arm/nxp/nxp_mcxe31x_common.dtsi:789 */
				gpiob_l: gpio@1706 {
					compatible = "nxp,siul2-gpio";      /* in zephyr/dts/arm/nxp/nxp_mcxe31x_common.dtsi:790 */
					reg = < 0x1706 0x2 >,
					      < 0x2c0 0x40 >;               /* in zephyr/dts/arm/nxp/nxp_mcxe31x_common.dtsi:791 */
					reg-names = "pgpdo",
					            "mscr";                 /* in zephyr/dts/arm/nxp/nxp_mcxe31x_common.dtsi:792 */
					interrupt-parent = < &eirq0 >;      /* in zephyr/dts/arm/nxp/nxp_mcxe31x_common.dtsi:793 */
					interrupts = < 0x0 0x8 >,
					             < 0x1 0x9 >,
					             < 0x2 0xa >,
					             < 0x3 0xb >,
					             < 0x4 0xc >,
					             < 0x5 0xd >,
					             < 0x8 0xe >,
					             < 0x9 0xf >,
					             < 0xa 0x18 >,
					             < 0xb 0x19 >,
					             < 0xc 0x1a >,
					             < 0xd 0x1b >,
					             < 0xe 0x1c >,
					             < 0xf 0x1d >;          /* in zephyr/dts/arm/nxp/nxp_mcxe31x_common.dtsi:794 */
					nxp,wkpu = < &wkpu >;               /* in zephyr/dts/arm/nxp/nxp_mcxe31x_common.dtsi:797 */
					nxp,wkpu-interrupts = < 0x0 0xb >,
					                      < 0x2 0xc >,
					                      < 0x8 0x1d >,
					                      < 0x9 0x15 >,
					                      < 0xb 0x14 >,
					                      < 0xc 0x10 >,
					                      < 0xd 0xf >,
					                      < 0xf 0x25 >; /* in zephyr/dts/arm/nxp/nxp_mcxe31x_common.dtsi:798 */
					gpio-controller;                    /* in zephyr/dts/arm/nxp/nxp_mcxe31x_common.dtsi:800 */
					#gpio-cells = < 0x2 >;              /* in zephyr/dts/arm/nxp/nxp_mcxe31x_common.dtsi:801 */
					ngpios = < 0x10 >;                  /* in zephyr/dts/arm/nxp/nxp_mcxe31x_common.dtsi:802 */
					gpio-reserved-ranges = < 0x6 0x2 >; /* in zephyr/dts/arm/nxp/nxp_mcxe31x_common.dtsi:803 */
					status = "disabled";                /* in zephyr/dts/arm/nxp/nxp_mcxe31x_common.dtsi:804 */
				};

				/* node '/soc/peripheral@40000000/siul2@290000/gpio@1704' defined in zephyr/dts/arm/nxp/nxp_mcxe31x_common.dtsi:807 */
				gpiob_h: gpio@1704 {
					compatible = "nxp,siul2-gpio";      /* in zephyr/dts/arm/nxp/nxp_mcxe31x_common.dtsi:808 */
					reg = < 0x1704 0x2 >,
					      < 0x300 0x40 >;               /* in zephyr/dts/arm/nxp/nxp_mcxe31x_common.dtsi:809 */
					reg-names = "pgpdo",
					            "mscr";                 /* in zephyr/dts/arm/nxp/nxp_mcxe31x_common.dtsi:810 */
					interrupt-parent = < &eirq0 >;      /* in zephyr/dts/arm/nxp/nxp_mcxe31x_common.dtsi:811 */
					interrupts = < 0x0 0x1e >,
					             < 0x1 0x1f >,
					             < 0x5 0x8 >,
					             < 0x6 0x9 >,
					             < 0x7 0xa >,
					             < 0x8 0xb >,
					             < 0x9 0xc >,
					             < 0xa 0xd >,
					             < 0xc 0xe >,
					             < 0xf 0xf >;           /* in zephyr/dts/arm/nxp/nxp_mcxe31x_common.dtsi:812 */
					nxp,wkpu = < &wkpu >;               /* in zephyr/dts/arm/nxp/nxp_mcxe31x_common.dtsi:814 */
					nxp,wkpu-interrupts = < 0x0 0x11 >,
					                      < 0x1 0x12 >,
					                      < 0x3 0x2a >,
					                      < 0x5 0x2b >,
					                      < 0x7 0x2c >,
					                      < 0xa 0x2d >,
					                      < 0xc 0x2e >; /* in zephyr/dts/arm/nxp/nxp_mcxe31x_common.dtsi:815 */
					gpio-controller;                    /* in zephyr/dts/arm/nxp/nxp_mcxe31x_common.dtsi:817 */
					#gpio-cells = < 0x2 >;              /* in zephyr/dts/arm/nxp/nxp_mcxe31x_common.dtsi:818 */
					ngpios = < 0x10 >;                  /* in zephyr/dts/arm/nxp/nxp_mcxe31x_common.dtsi:819 */
					status = "okay";                    /* in zephyr/boards/nxp/frdm_mcxe31b/frdm_mcxe31b.dts:101 */
					phandle = < 0x9 >;                  /* in zephyr/boards/nxp/frdm_mcxe31b/frdm_mcxe31b.dts:46 */
				};

				/* node '/soc/peripheral@40000000/siul2@290000/gpio@170a' defined in zephyr/dts/arm/nxp/nxp_mcxe31x_common.dtsi:823 */
				gpioc_l: gpio@170a {
					compatible = "nxp,siul2-gpio";      /* in zephyr/dts/arm/nxp/nxp_mcxe31x_common.dtsi:824 */
					reg = < 0x170a 0x2 >,
					      < 0x340 0x40 >;               /* in zephyr/dts/arm/nxp/nxp_mcxe31x_common.dtsi:825 */
					reg-names = "pgpdo",
					            "mscr";                 /* in zephyr/dts/arm/nxp/nxp_mcxe31x_common.dtsi:826 */
					interrupt-parent = < &eirq0 >;      /* in zephyr/dts/arm/nxp/nxp_mcxe31x_common.dtsi:827 */
					interrupts = < 0x0 0x1 >,
					             < 0x1 0x1 >,
					             < 0x2 0x2 >,
					             < 0x3 0x3 >,
					             < 0x4 0x4 >,
					             < 0x5 0x5 >,
					             < 0x6 0x6 >,
					             < 0x7 0x7 >,
					             < 0x8 0x10 >,
					             < 0x9 0x11 >,
					             < 0xa 0x12 >,
					             < 0xb 0x13 >,
					             < 0xc 0x14 >,
					             < 0xd 0x15 >,
					             < 0xe 0x16 >,
					             < 0xf 0x17 >;          /* in zephyr/dts/arm/nxp/nxp_mcxe31x_common.dtsi:828 */
					nxp,wkpu = < &wkpu >;               /* in zephyr/dts/arm/nxp/nxp_mcxe31x_common.dtsi:832 */
					nxp,wkpu-interrupts = < 0x6 0x7 >,
					                      < 0x7 0x6 >,
					                      < 0x9 0xe >,
					                      < 0xb 0x16 >; /* in zephyr/dts/arm/nxp/nxp_mcxe31x_common.dtsi:833 */
					gpio-controller;                    /* in zephyr/dts/arm/nxp/nxp_mcxe31x_common.dtsi:834 */
					#gpio-cells = < 0x2 >;              /* in zephyr/dts/arm/nxp/nxp_mcxe31x_common.dtsi:835 */
					ngpios = < 0x10 >;                  /* in zephyr/dts/arm/nxp/nxp_mcxe31x_common.dtsi:836 */
					status = "okay";                    /* in zephyr/boards/nxp/frdm_mcxe31b/frdm_mcxe31b.dts:114 */
					phandle = < 0xa >;                  /* in zephyr/boards/nxp/frdm_mcxe31b/frdm_mcxe31b.dts:51 */
				};

				/* node '/soc/peripheral@40000000/siul2@290000/gpio@1708' defined in zephyr/dts/arm/nxp/nxp_mcxe31x_common.dtsi:840 */
				gpioc_h: gpio@1708 {
					compatible = "nxp,siul2-gpio";      /* in zephyr/dts/arm/nxp/nxp_mcxe31x_common.dtsi:841 */
					reg = < 0x1708 0x2 >,
					      < 0x380 0x40 >;               /* in zephyr/dts/arm/nxp/nxp_mcxe31x_common.dtsi:842 */
					reg-names = "pgpdo",
					            "mscr";                 /* in zephyr/dts/arm/nxp/nxp_mcxe31x_common.dtsi:843 */
					interrupt-parent = < &eirq0 >;      /* in zephyr/dts/arm/nxp/nxp_mcxe31x_common.dtsi:844 */
					interrupts = < 0x4 0x10 >,
					             < 0x5 0x11 >,
					             < 0x7 0x12 >,
					             < 0x8 0x13 >,
					             < 0x9 0x14 >,
					             < 0xa 0x15 >,
					             < 0xb 0x16 >,
					             < 0xd 0x17 >;          /* in zephyr/dts/arm/nxp/nxp_mcxe31x_common.dtsi:845 */
					nxp,wkpu = < &wkpu >;               /* in zephyr/dts/arm/nxp/nxp_mcxe31x_common.dtsi:847 */
					nxp,wkpu-interrupts = < 0x2 0x28 >,
					                      < 0x4 0x2f >,
					                      < 0x7 0x30 >,
					                      < 0x8 0x32 >,
					                      < 0x9 0x31 >,
					                      < 0xa 0x34 >,
					                      < 0xd 0x33 >,
					                      < 0xf 0x35 >; /* in zephyr/dts/arm/nxp/nxp_mcxe31x_common.dtsi:848 */
					gpio-controller;                    /* in zephyr/dts/arm/nxp/nxp_mcxe31x_common.dtsi:850 */
					#gpio-cells = < 0x2 >;              /* in zephyr/dts/arm/nxp/nxp_mcxe31x_common.dtsi:851 */
					ngpios = < 0x10 >;                  /* in zephyr/dts/arm/nxp/nxp_mcxe31x_common.dtsi:852 */
					status = "okay";                    /* in zephyr/boards/nxp/frdm_mcxe31b/frdm_mcxe31b.dts:118 */
					phandle = < 0x8 >;                  /* in zephyr/boards/nxp/frdm_mcxe31b/frdm_mcxe31b.dts:41 */
				};

				/* node '/soc/peripheral@40000000/siul2@290000/gpio@170e' defined in zephyr/dts/arm/nxp/nxp_mcxe31x_common.dtsi:856 */
				gpiod_l: gpio@170e {
					compatible = "nxp,siul2-gpio";      /* in zephyr/dts/arm/nxp/nxp_mcxe31x_common.dtsi:857 */
					reg = < 0x170e 0x2 >,
					      < 0x3c0 0x40 >;               /* in zephyr/dts/arm/nxp/nxp_mcxe31x_common.dtsi:858 */
					reg-names = "pgpdo",
					            "mscr";                 /* in zephyr/dts/arm/nxp/nxp_mcxe31x_common.dtsi:859 */
					interrupt-parent = < &eirq0 >;      /* in zephyr/dts/arm/nxp/nxp_mcxe31x_common.dtsi:860 */
					interrupts = < 0x0 0x8 >,
					             < 0x1 0x9 >,
					             < 0x2 0xa >,
					             < 0x3 0xb >,
					             < 0x4 0xc >,
					             < 0x5 0xd >,
					             < 0x6 0xe >,
					             < 0x7 0xf >,
					             < 0x8 0x18 >,
					             < 0x9 0x19 >,
					             < 0xa 0x1a >,
					             < 0xb 0x1b >,
					             < 0xc 0x1c >,
					             < 0xd 0x1d >,
					             < 0xe 0x1e >,
					             < 0xf 0x1f >;          /* in zephyr/dts/arm/nxp/nxp_mcxe31x_common.dtsi:861 */
					nxp,wkpu = < &wkpu >;               /* in zephyr/dts/arm/nxp/nxp_mcxe31x_common.dtsi:865 */
					nxp,wkpu-interrupts = < 0x0 0xa >,
					                      < 0x2 0xd >,
					                      < 0x3 0x5 >,
					                      < 0x4 0x1a >,
					                      < 0xd 0x1c >; /* in zephyr/dts/arm/nxp/nxp_mcxe31x_common.dtsi:866 */
					gpio-controller;                    /* in zephyr/dts/arm/nxp/nxp_mcxe31x_common.dtsi:868 */
					#gpio-cells = < 0x2 >;              /* in zephyr/dts/arm/nxp/nxp_mcxe31x_common.dtsi:869 */
					ngpios = < 0x10 >;                  /* in zephyr/dts/arm/nxp/nxp_mcxe31x_common.dtsi:870 */
					status = "okay";                    /* in zephyr/boards/nxp/frdm_mcxe31b/frdm_mcxe31b.dts:122 */
					phandle = < 0xb >;                  /* in zephyr/boards/nxp/frdm_mcxe31b/frdm_mcxe31b.dts:61 */
				};

				/* node '/soc/peripheral@40000000/siul2@290000/gpio@170c' defined in zephyr/dts/arm/nxp/nxp_mcxe31x_common.dtsi:874 */
				gpiod_h: gpio@170c {
					compatible = "nxp,siul2-gpio";      /* in zephyr/dts/arm/nxp/nxp_mcxe31x_common.dtsi:875 */
					reg = < 0x170c 0x2 >,
					      < 0x400 0x40 >;               /* in zephyr/dts/arm/nxp/nxp_mcxe31x_common.dtsi:876 */
					reg-names = "pgpdo",
					            "mscr";                 /* in zephyr/dts/arm/nxp/nxp_mcxe31x_common.dtsi:877 */
					interrupt-parent = < &eirq0 >;      /* in zephyr/dts/arm/nxp/nxp_mcxe31x_common.dtsi:878 */
					interrupts = < 0x1 0x18 >,
					             < 0x4 0x19 >,
					             < 0x5 0x1a >,
					             < 0x6 0x1b >,
					             < 0x7 0x1c >,
					             < 0x8 0x1d >,
					             < 0xb 0x1e >,
					             < 0xc 0x1f >;          /* in zephyr/dts/arm/nxp/nxp_mcxe31x_common.dtsi:879 */
					nxp,wkpu = < &wkpu >;               /* in zephyr/dts/arm/nxp/nxp_mcxe31x_common.dtsi:881 */
					nxp,wkpu-interrupts = < 0x4 0x3a >,
					                      < 0x7 0x36 >,
					                      < 0xb 0x37 >,
					                      < 0xd 0x38 >,
					                      < 0xf 0x39 >; /* in zephyr/dts/arm/nxp/nxp_mcxe31x_common.dtsi:882 */
					gpio-controller;                    /* in zephyr/dts/arm/nxp/nxp_mcxe31x_common.dtsi:884 */
					#gpio-cells = < 0x2 >;              /* in zephyr/dts/arm/nxp/nxp_mcxe31x_common.dtsi:885 */
					ngpios = < 0x10 >;                  /* in zephyr/dts/arm/nxp/nxp_mcxe31x_common.dtsi:886 */
					status = "disabled";                /* in zephyr/dts/arm/nxp/nxp_mcxe31x_common.dtsi:887 */
				};

				/* node '/soc/peripheral@40000000/siul2@290000/gpio@1712' defined in zephyr/dts/arm/nxp/nxp_mcxe31x_common.dtsi:890 */
				gpioe_l: gpio@1712 {
					compatible = "nxp,siul2-gpio";      /* in zephyr/dts/arm/nxp/nxp_mcxe31x_common.dtsi:891 */
					reg = < 0x1712 0x2 >,
					      < 0x440 0x40 >;               /* in zephyr/dts/arm/nxp/nxp_mcxe31x_common.dtsi:892 */
					reg-names = "pgpdo",
					            "mscr";                 /* in zephyr/dts/arm/nxp/nxp_mcxe31x_common.dtsi:893 */
					interrupt-parent = < &eirq0 >;      /* in zephyr/dts/arm/nxp/nxp_mcxe31x_common.dtsi:894 */
					interrupts = < 0x0 0x0 >,
					             < 0x1 0x1 >,
					             < 0x2 0x2 >,
					             < 0x3 0x3 >,
					             < 0x4 0x4 >,
					             < 0x5 0x5 >,
					             < 0x6 0x6 >,
					             < 0x8 0x7 >,
					             < 0x9 0x8 >,
					             < 0xa 0x9 >,
					             < 0xb 0xa >,
					             < 0xc 0xb >,
					             < 0xd 0xc >,
					             < 0xe 0xd >,
					             < 0xf 0xe >;           /* in zephyr/dts/arm/nxp/nxp_mcxe31x_common.dtsi:895 */
					nxp,wkpu = < &wkpu >;               /* in zephyr/dts/arm/nxp/nxp_mcxe31x_common.dtsi:899 */
					nxp,wkpu-interrupts = < 0x0 0x1e >,
					                      < 0x2 0x1f >,
					                      < 0x5 0x24 >,
					                      < 0x6 0x21 >,
					                      < 0xb 0x20 >,
					                      < 0xe 0x22 >; /* in zephyr/dts/arm/nxp/nxp_mcxe31x_common.dtsi:900 */
					gpio-controller;                    /* in zephyr/dts/arm/nxp/nxp_mcxe31x_common.dtsi:902 */
					#gpio-cells = < 0x2 >;              /* in zephyr/dts/arm/nxp/nxp_mcxe31x_common.dtsi:903 */
					ngpios = < 0x10 >;                  /* in zephyr/dts/arm/nxp/nxp_mcxe31x_common.dtsi:904 */
					status = "disabled";                /* in zephyr/dts/arm/nxp/nxp_mcxe31x_common.dtsi:905 */
					phandle = < 0xd >;                  /* in zephyr/boards/nxp/frdm_mcxe31b/frdm_mcxe31b.dts:71 */
				};

				/* node '/soc/peripheral@40000000/siul2@290000/gpio@1710' defined in zephyr/dts/arm/nxp/nxp_mcxe31x_common.dtsi:908 */
				gpioe_h: gpio@1710 {
					compatible = "nxp,siul2-gpio";      /* in zephyr/dts/arm/nxp/nxp_mcxe31x_common.dtsi:909 */
					reg = < 0x1710 0x2 >,
					      < 0x480 0x40 >;               /* in zephyr/dts/arm/nxp/nxp_mcxe31x_common.dtsi:910 */
					reg-names = "pgpdo",
					            "mscr";                 /* in zephyr/dts/arm/nxp/nxp_mcxe31x_common.dtsi:911 */
					interrupt-parent = < &eirq0 >;      /* in zephyr/dts/arm/nxp/nxp_mcxe31x_common.dtsi:912 */
					interrupts = < 0x0 0xf >;           /* in zephyr/dts/arm/nxp/nxp_mcxe31x_common.dtsi:913 */
					nxp,wkpu = < &wkpu >;               /* in zephyr/dts/arm/nxp/nxp_mcxe31x_common.dtsi:914 */
					nxp,wkpu-interrupts = < 0x0 0x17 >,
					                      < 0x2 0x3b >,
					                      < 0x5 0x3c >,
					                      < 0x7 0x3d >,
					                      < 0x9 0x3e >; /* in zephyr/dts/arm/nxp/nxp_mcxe31x_common.dtsi:915 */
					gpio-controller;                    /* in zephyr/dts/arm/nxp/nxp_mcxe31x_common.dtsi:917 */
					#gpio-cells = < 0x2 >;              /* in zephyr/dts/arm/nxp/nxp_mcxe31x_common.dtsi:918 */
					ngpios = < 0x10 >;                  /* in zephyr/dts/arm/nxp/nxp_mcxe31x_common.dtsi:919 */
					status = "disabled";                /* in zephyr/dts/arm/nxp/nxp_mcxe31x_common.dtsi:920 */
					phandle = < 0xc >;                  /* in zephyr/boards/nxp/frdm_mcxe31b/frdm_mcxe31b.dts:71 */
				};

				/* node '/soc/peripheral@40000000/siul2@290000/gpio@1716' defined in zephyr/dts/arm/nxp/nxp_mcxe31x_common.dtsi:923 */
				gpiof_l: gpio@1716 {
					compatible = "nxp,siul2-gpio"; /* in zephyr/dts/arm/nxp/nxp_mcxe31x_common.dtsi:924 */
					reg = < 0x1716 0x2 >,
					      < 0x4c0 0x40 >;          /* in zephyr/dts/arm/nxp/nxp_mcxe31x_common.dtsi:925 */
					reg-names = "pgpdo",
					            "mscr";            /* in zephyr/dts/arm/nxp/nxp_mcxe31x_common.dtsi:926 */
					interrupt-parent = < &eirq0 >; /* in zephyr/dts/arm/nxp/nxp_mcxe31x_common.dtsi:927 */
					interrupts = < 0x0 0x0 >,
					             < 0x1 0x1 >,
					             < 0x2 0x2 >,
					             < 0x3 0x3 >,
					             < 0x4 0x4 >,
					             < 0x5 0x5 >,
					             < 0x6 0x6 >,
					             < 0x7 0x7 >,
					             < 0x8 0x10 >,
					             < 0x9 0x11 >,
					             < 0xa 0x12 >,
					             < 0xb 0x13 >,
					             < 0xc 0x14 >,
					             < 0xd 0x15 >,
					             < 0xe 0x16 >,
					             < 0xf 0x17 >;     /* in zephyr/dts/arm/nxp/nxp_mcxe31x_common.dtsi:928 */
					gpio-controller;               /* in zephyr/dts/arm/nxp/nxp_mcxe31x_common.dtsi:932 */
					#gpio-cells = < 0x2 >;         /* in zephyr/dts/arm/nxp/nxp_mcxe31x_common.dtsi:933 */
					ngpios = < 0x10 >;             /* in zephyr/dts/arm/nxp/nxp_mcxe31x_common.dtsi:934 */
					status = "disabled";           /* in zephyr/dts/arm/nxp/nxp_mcxe31x_common.dtsi:935 */
				};

				/* node '/soc/peripheral@40000000/siul2@290000/gpio@1714' defined in zephyr/dts/arm/nxp/nxp_mcxe31x_common.dtsi:938 */
				gpiof_h: gpio@1714 {
					compatible = "nxp,siul2-gpio"; /* in zephyr/dts/arm/nxp/nxp_mcxe31x_common.dtsi:939 */
					reg = < 0x1714 0x2 >,
					      < 0x500 0x40 >;          /* in zephyr/dts/arm/nxp/nxp_mcxe31x_common.dtsi:940 */
					reg-names = "pgpdo",
					            "mscr";            /* in zephyr/dts/arm/nxp/nxp_mcxe31x_common.dtsi:941 */
					gpio-controller;               /* in zephyr/dts/arm/nxp/nxp_mcxe31x_common.dtsi:942 */
					#gpio-cells = < 0x2 >;         /* in zephyr/dts/arm/nxp/nxp_mcxe31x_common.dtsi:943 */
					ngpios = < 0x10 >;             /* in zephyr/dts/arm/nxp/nxp_mcxe31x_common.dtsi:944 */
					status = "disabled";           /* in zephyr/dts/arm/nxp/nxp_mcxe31x_common.dtsi:945 */
				};

				/* node '/soc/peripheral@40000000/siul2@290000/gpio@171a' defined in zephyr/dts/arm/nxp/nxp_mcxe31x_common.dtsi:948 */
				gpiog_l: gpio@171a {
					compatible = "nxp,siul2-gpio"; /* in zephyr/dts/arm/nxp/nxp_mcxe31x_common.dtsi:949 */
					reg = < 0x171a 0x2 >,
					      < 0x540 0x40 >;          /* in zephyr/dts/arm/nxp/nxp_mcxe31x_common.dtsi:950 */
					reg-names = "pgpdo",
					            "mscr";            /* in zephyr/dts/arm/nxp/nxp_mcxe31x_common.dtsi:951 */
					interrupt-parent = < &eirq0 >; /* in zephyr/dts/arm/nxp/nxp_mcxe31x_common.dtsi:952 */
					interrupts = < 0x0 0x8 >,
					             < 0x1 0x9 >,
					             < 0x2 0xa >,
					             < 0x3 0xb >,
					             < 0x4 0xc >,
					             < 0x5 0xd >,
					             < 0x6 0xe >,
					             < 0x7 0xf >,
					             < 0x8 0x18 >,
					             < 0x9 0x19 >,
					             < 0xa 0x1a >,
					             < 0xb 0x1b >,
					             < 0xc 0x1c >,
					             < 0xd 0x1d >,
					             < 0xe 0x1e >,
					             < 0xf 0x1f >;     /* in zephyr/dts/arm/nxp/nxp_mcxe31x_common.dtsi:953 */
					gpio-controller;               /* in zephyr/dts/arm/nxp/nxp_mcxe31x_common.dtsi:957 */
					#gpio-cells = < 0x2 >;         /* in zephyr/dts/arm/nxp/nxp_mcxe31x_common.dtsi:958 */
					ngpios = < 0x10 >;             /* in zephyr/dts/arm/nxp/nxp_mcxe31x_common.dtsi:959 */
					status = "disabled";           /* in zephyr/dts/arm/nxp/nxp_mcxe31x_common.dtsi:960 */
				};

				/* node '/soc/peripheral@40000000/siul2@290000/gpio@1718' defined in zephyr/dts/arm/nxp/nxp_mcxe31x_common.dtsi:963 */
				gpiog_h: gpio@1718 {
					compatible = "nxp,siul2-gpio"; /* in zephyr/dts/arm/nxp/nxp_mcxe31x_common.dtsi:964 */
					reg = < 0x1718 0x2 >,
					      < 0x580 0x40 >;          /* in zephyr/dts/arm/nxp/nxp_mcxe31x_common.dtsi:965 */
					reg-names = "pgpdo",
					            "mscr";            /* in zephyr/dts/arm/nxp/nxp_mcxe31x_common.dtsi:966 */
					gpio-controller;               /* in zephyr/dts/arm/nxp/nxp_mcxe31x_common.dtsi:967 */
					#gpio-cells = < 0x2 >;         /* in zephyr/dts/arm/nxp/nxp_mcxe31x_common.dtsi:968 */
					ngpios = < 0x10 >;             /* in zephyr/dts/arm/nxp/nxp_mcxe31x_common.dtsi:969 */
					status = "disabled";           /* in zephyr/dts/arm/nxp/nxp_mcxe31x_common.dtsi:970 */
				};
			};

			/* node '/soc/peripheral@40000000/stcu@3a0000' defined in zephyr/dts/arm/nxp/nxp_mcxe31x_common.dtsi:974 */
			stcu: stcu@3a0000 {
				compatible = "nxp,stcu";   /* in zephyr/dts/arm/nxp/nxp_mcxe31x_common.dtsi:975 */
				reg = < 0x3a0000 0x2260 >; /* in zephyr/dts/arm/nxp/nxp_mcxe31x_common.dtsi:976 */
				status = "disabled";       /* in zephyr/dts/arm/nxp/nxp_mcxe31x_common.dtsi:977 */
			};

			/* node '/soc/peripheral@40000000/stm@274000' defined in zephyr/dts/arm/nxp/nxp_mcxe31x_common.dtsi:980 */
			stm_0: stm@274000 {
				compatible = "nxp,stm";      /* in zephyr/dts/arm/nxp/nxp_mcxe31x_common.dtsi:981 */
				reg = < 0x274000 0x68 >;     /* in zephyr/dts/arm/nxp/nxp_mcxe31x_common.dtsi:982 */
				interrupts = < 0x27 0x0 >;   /* in zephyr/dts/arm/nxp/nxp_mcxe31x_common.dtsi:983 */
				clocks = < &mc_cgm 0x2b00 >; /* in zephyr/dts/arm/nxp/nxp_mcxe31x_common.dtsi:984 */
				status = "okay";             /* in zephyr/boards/nxp/frdm_mcxe31b/frdm_mcxe31b.dts:174 */
				prescaler = < 0x1 >;         /* in zephyr/boards/nxp/frdm_mcxe31b/frdm_mcxe31b.dts:175 */
			};

			/* node '/soc/peripheral@40000000/stm@474000' defined in zephyr/dts/arm/nxp/nxp_mcxe31x_common.dtsi:988 */
			stm_1: stm@474000 {
				compatible = "nxp,stm";      /* in zephyr/dts/arm/nxp/nxp_mcxe31x_common.dtsi:989 */
				reg = < 0x474000 0x68 >;     /* in zephyr/dts/arm/nxp/nxp_mcxe31x_common.dtsi:990 */
				interrupts = < 0x28 0x0 >;   /* in zephyr/dts/arm/nxp/nxp_mcxe31x_common.dtsi:991 */
				clocks = < &mc_cgm 0x2b01 >; /* in zephyr/dts/arm/nxp/nxp_mcxe31x_common.dtsi:992 */
				status = "disabled";         /* in zephyr/dts/arm/nxp/nxp_mcxe31x_common.dtsi:993 */
			};

			/* node '/soc/peripheral@40000000/swt@270000' defined in zephyr/dts/arm/nxp/nxp_mcxe31x_common.dtsi:996 */
			swt_0: swt@270000 {
				compatible = "nxp,swt";    /* in zephyr/dts/arm/nxp/nxp_mcxe31x_common.dtsi:997 */
				reg = < 0x270000 0x3c >;   /* in zephyr/dts/arm/nxp/nxp_mcxe31x_common.dtsi:998 */
				interrupts = < 0x2a 0x0 >; /* in zephyr/dts/arm/nxp/nxp_mcxe31x_common.dtsi:999 */
				status = "disabled";       /* in zephyr/dts/arm/nxp/nxp_mcxe31x_common.dtsi:1000 */
			};

			/* node '/soc/peripheral@40000000/sxosc@402cc000' defined in zephyr/dts/arm/nxp/nxp_mcxe31x_common.dtsi:1003 */
			sxosc: sxosc@402cc000 {
				compatible = "nxp,sxosc";  /* in zephyr/dts/arm/nxp/nxp_mcxe31x_common.dtsi:1004 */
				reg = < 0x402cc000 0x24 >; /* in zephyr/dts/arm/nxp/nxp_mcxe31x_common.dtsi:1005 */
				status = "disabled";       /* in zephyr/dts/arm/nxp/nxp_mcxe31x_common.dtsi:1006 */
			};

			/* node '/soc/peripheral@40000000/tempsense@37c000' defined in zephyr/dts/arm/nxp/nxp_mcxe31x_common.dtsi:1009 */
			tempsense: tempsense@37c000 {
				compatible = "nxp,tempsense"; /* in zephyr/dts/arm/nxp/nxp_mcxe31x_common.dtsi:1010 */
				reg = < 0x37c000 0x30 >;      /* in zephyr/dts/arm/nxp/nxp_mcxe31x_common.dtsi:1011 */
				status = "disabled";          /* in zephyr/dts/arm/nxp/nxp_mcxe31x_common.dtsi:1012 */
			};

			/* node '/soc/peripheral@40000000/trgmux@80000' defined in zephyr/dts/arm/nxp/nxp_mcxe31x_common.dtsi:1015 */
			trgmux: trgmux@80000 {
				compatible = "nxp,trgmux"; /* in zephyr/dts/arm/nxp/nxp_mcxe31x_common.dtsi:1016 */
				reg = < 0x80000 0xbc >;    /* in zephyr/dts/arm/nxp/nxp_mcxe31x_common.dtsi:1017 */
				status = "disabled";       /* in zephyr/dts/arm/nxp/nxp_mcxe31x_common.dtsi:1018 */
			};

			/* node '/soc/peripheral@40000000/tspc@2c4000' defined in zephyr/dts/arm/nxp/nxp_mcxe31x_common.dtsi:1021 */
			tspc: tspc@2c4000 {
				compatible = "nxp,tspc"; /* in zephyr/dts/arm/nxp/nxp_mcxe31x_common.dtsi:1022 */
				reg = < 0x2c4000 0xc4 >; /* in zephyr/dts/arm/nxp/nxp_mcxe31x_common.dtsi:1023 */
				status = "disabled";     /* in zephyr/dts/arm/nxp/nxp_mcxe31x_common.dtsi:1024 */
			};

			/* node '/soc/peripheral@40000000/virt-wrapper@2a8000' defined in zephyr/dts/arm/nxp/nxp_mcxe31x_common.dtsi:1027 */
			virt_wrapper: virt-wrapper@2a8000 {
				compatible = "nxp,virt-wrapper"; /* in zephyr/dts/arm/nxp/nxp_mcxe31x_common.dtsi:1028 */
				reg = < 0x2a8000 0x124 >;        /* in zephyr/dts/arm/nxp/nxp_mcxe31x_common.dtsi:1029 */
				status = "disabled";             /* in zephyr/dts/arm/nxp/nxp_mcxe31x_common.dtsi:1030 */
			};

			/* node '/soc/peripheral@40000000/wkpu@2b4000' defined in zephyr/dts/arm/nxp/nxp_mcxe31x_common.dtsi:1033 */
			wkpu: wkpu@2b4000 {
				compatible = "nxp,wkpu";   /* in zephyr/dts/arm/nxp/nxp_mcxe31x_common.dtsi:1034 */
				reg = < 0x2b4000 0x90 >;   /* in zephyr/dts/arm/nxp/nxp_mcxe31x_common.dtsi:1035 */
				interrupts = < 0x53 0x0 >; /* in zephyr/dts/arm/nxp/nxp_mcxe31x_common.dtsi:1036 */
				status = "disabled";       /* in zephyr/dts/arm/nxp/nxp_mcxe31x_common.dtsi:1037 */
				phandle = < 0x7 >;         /* in zephyr/dts/arm/nxp/nxp_mcxe31x_common.dtsi:764 */
			};

			/* node '/soc/peripheral@40000000/xbic@204000' defined in zephyr/dts/arm/nxp/nxp_mcxe31x_common.dtsi:1040 */
			xbic_axbs: xbic@204000 {
				compatible = "nxp,xbic"; /* in zephyr/dts/arm/nxp/nxp_mcxe31x_common.dtsi:1041 */
				reg = < 0x204000 0x2c >; /* in zephyr/dts/arm/nxp/nxp_mcxe31x_common.dtsi:1042 */
				status = "disabled";     /* in zephyr/dts/arm/nxp/nxp_mcxe31x_common.dtsi:1043 */
			};

			/* node '/soc/peripheral@40000000/xbic@404000' defined in zephyr/dts/arm/nxp/nxp_mcxe31x_common.dtsi:1046 */
			xbic_axbs_edma: xbic@404000 {
				compatible = "nxp,xbic"; /* in zephyr/dts/arm/nxp/nxp_mcxe31x_common.dtsi:1047 */
				reg = < 0x404000 0x2c >; /* in zephyr/dts/arm/nxp/nxp_mcxe31x_common.dtsi:1048 */
				status = "disabled";     /* in zephyr/dts/arm/nxp/nxp_mcxe31x_common.dtsi:1049 */
			};

			/* node '/soc/peripheral@40000000/xbic@208000' defined in zephyr/dts/arm/nxp/nxp_mcxe31x_common.dtsi:1052 */
			xbic_axbs_peri: xbic@208000 {
				compatible = "nxp,xbic"; /* in zephyr/dts/arm/nxp/nxp_mcxe31x_common.dtsi:1053 */
				reg = < 0x208000 0x2c >; /* in zephyr/dts/arm/nxp/nxp_mcxe31x_common.dtsi:1054 */
				status = "disabled";     /* in zephyr/dts/arm/nxp/nxp_mcxe31x_common.dtsi:1055 */
			};

			/* node '/soc/peripheral@40000000/xbic@400000' defined in zephyr/dts/arm/nxp/nxp_mcxe31x_common.dtsi:1058 */
			xbic_axbs_tcm: xbic@400000 {
				compatible = "nxp,xbic"; /* in zephyr/dts/arm/nxp/nxp_mcxe31x_common.dtsi:1059 */
				reg = < 0x400000 0x2c >; /* in zephyr/dts/arm/nxp/nxp_mcxe31x_common.dtsi:1060 */
				status = "disabled";     /* in zephyr/dts/arm/nxp/nxp_mcxe31x_common.dtsi:1061 */
			};

			/* node '/soc/peripheral@40000000/xrdc@278000' defined in zephyr/dts/arm/nxp/nxp_mcxe31x_common.dtsi:1064 */
			xrdc: xrdc@278000 {
				compatible = "nxp,xrdc";   /* in zephyr/dts/arm/nxp/nxp_mcxe31x_common.dtsi:1065 */
				reg = < 0x278000 0x248c >; /* in zephyr/dts/arm/nxp/nxp_mcxe31x_common.dtsi:1066 */
				status = "disabled";       /* in zephyr/dts/arm/nxp/nxp_mcxe31x_common.dtsi:1067 */
			};
		};

		/* node '/soc/interrupt-controller@e000e100' defined in zephyr/dts/arm/armv7-m.dtsi:13 */
		nvic: interrupt-controller@e000e100 {
			#address-cells = < 0x1 >;            /* in zephyr/dts/arm/armv7-m.dtsi:14 */
			compatible = "arm,v7m-nvic";         /* in zephyr/dts/arm/armv7-m.dtsi:15 */
			reg = < 0xe000e100 0xc00 >;          /* in zephyr/dts/arm/armv7-m.dtsi:16 */
			interrupt-controller;                /* in zephyr/dts/arm/armv7-m.dtsi:17 */
			#interrupt-cells = < 0x2 >;          /* in zephyr/dts/arm/armv7-m.dtsi:18 */
			arm,num-irq-priority-bits = < 0x4 >; /* in zephyr/dts/arm/nxp/nxp_mcxe31x_common.dtsi:1072 */
			phandle = < 0x1 >;                   /* in zephyr/dts/arm/armv7-m.dtsi:10 */
		};

		/* node '/soc/timer@e000e010' defined in zephyr/dts/arm/armv7-m.dtsi:21 */
		systick: timer@e000e010 {
			compatible = "arm,armv7m-systick"; /* in zephyr/dts/arm/armv7-m.dtsi:22 */
			reg = < 0xe000e010 0x10 >;         /* in zephyr/dts/arm/armv7-m.dtsi:23 */
		};
	};

	/* node '/chosen' defined in zephyr/dts/common/skeleton.dtsi:13 */
	chosen {
		zephyr,sram = &sram;              /* in zephyr/boards/nxp/frdm_mcxe31b/frdm_mcxe31b.dts:28 */
		zephyr,itcm = &itcm;              /* in zephyr/boards/nxp/frdm_mcxe31b/frdm_mcxe31b.dts:29 */
		zephyr,dtcm = &dtcm;              /* in zephyr/boards/nxp/frdm_mcxe31b/frdm_mcxe31b.dts:30 */
		zephyr,flash = &program_flash;    /* in zephyr/boards/nxp/frdm_mcxe31b/frdm_mcxe31b.dts:31 */
		zephyr,flash-controller = &flash; /* in zephyr/boards/nxp/frdm_mcxe31b/frdm_mcxe31b.dts:32 */
		zephyr,console = &lpuart_5;       /* in zephyr/boards/nxp/frdm_mcxe31b/frdm_mcxe31b.dts:33 */
		zephyr,shell-uart = &lpuart_5;    /* in zephyr/boards/nxp/frdm_mcxe31b/frdm_mcxe31b.dts:34 */
	};

	/* node '/aliases' defined in zephyr/dts/common/skeleton.dtsi:15 */
	aliases {
		led0 = &red_led;    /* in zephyr/boards/nxp/frdm_mcxe31b/frdm_mcxe31b.dts:20 */
		led1 = &green_led;  /* in zephyr/boards/nxp/frdm_mcxe31b/frdm_mcxe31b.dts:21 */
		led2 = &blue_led;   /* in zephyr/boards/nxp/frdm_mcxe31b/frdm_mcxe31b.dts:22 */
		sw0 = &user_button; /* in zephyr/boards/nxp/frdm_mcxe31b/frdm_mcxe31b.dts:23 */
		rtc = &counter_rtc; /* in zephyr/boards/nxp/frdm_mcxe31b/frdm_mcxe31b.dts:24 */
	};

	/* node '/cpus' defined in zephyr/dts/arm/nxp/nxp_mcxe31x_common.dtsi:12 */
	cpus {
		#address-cells = < 0x1 >; /* in zephyr/dts/arm/nxp/nxp_mcxe31x_common.dtsi:13 */
		#size-cells = < 0x0 >;    /* in zephyr/dts/arm/nxp/nxp_mcxe31x_common.dtsi:14 */

		/* node '/cpus/cpu@0' defined in zephyr/dts/arm/nxp/nxp_mcxe31x_common.dtsi:16 */
		core0: cpu@0 {
			reg = < 0x0 >;                   /* in zephyr/dts/arm/nxp/nxp_mcxe31x_common.dtsi:17 */
			device_type = "cpu";             /* in zephyr/dts/arm/nxp/nxp_mcxe31x_common.dtsi:18 */
			compatible = "arm,cortex-m7";    /* in zephyr/dts/arm/nxp/nxp_mcxe31x_common.dtsi:19 */
			clock-frequency = < 0x9896800 >; /* in zephyr/boards/nxp/frdm_mcxe31b/frdm_mcxe31b.dts:97 */
		};
	};

	/* node '/pinctrl' defined in zephyr/dts/arm/nxp/nxp_mcxe31x_common.dtsi:24 */
	pinctrl: pinctrl {
		compatible = "nxp,mcxe31x-siul2-pinctrl"; /* in zephyr/dts/arm/nxp/nxp_mcxe31x_common.dtsi:25 */
		status = "okay";                          /* in zephyr/dts/arm/nxp/nxp_mcxe31x_common.dtsi:26 */

		/* node '/pinctrl/eirq0_default' defined in zephyr/boards/nxp/frdm_mcxe31b/frdm_mcxe31b-pinctrl.dtsi:10 */
		eirq0_default: eirq0_default {
			phandle = < 0x5 >; /* in zephyr/boards/nxp/frdm_mcxe31b/frdm_mcxe31b.dts:126 */

			/* node '/pinctrl/eirq0_default/group1' defined in zephyr/boards/nxp/frdm_mcxe31b/frdm_mcxe31b-pinctrl.dtsi:11 */
			group1 {
				pinmux = < 0x650e98 >; /* in zephyr/boards/nxp/frdm_mcxe31b/frdm_mcxe31b-pinctrl.dtsi:12 */
				input-enable;          /* in zephyr/boards/nxp/frdm_mcxe31b/frdm_mcxe31b-pinctrl.dtsi:13 */
			};
		};

		/* node '/pinctrl/pinmux_lpuart_5' defined in zephyr/boards/nxp/frdm_mcxe31b/frdm_mcxe31b-pinctrl.dtsi:17 */
		pinmux_lpuart_5: pinmux_lpuart_5 {
			phandle = < 0x3 >; /* in zephyr/boards/nxp/frdm_mcxe31b/frdm_mcxe31b.dts:107 */

			/* node '/pinctrl/pinmux_lpuart_5/group1' defined in zephyr/boards/nxp/frdm_mcxe31b/frdm_mcxe31b-pinctrl.dtsi:18 */
			group1 {
				pinmux = < 0x8e0004 >; /* in zephyr/boards/nxp/frdm_mcxe31b/frdm_mcxe31b-pinctrl.dtsi:19 */
				output-enable;         /* in zephyr/boards/nxp/frdm_mcxe31b/frdm_mcxe31b-pinctrl.dtsi:20 */
			};

			/* node '/pinctrl/pinmux_lpuart_5/group2' defined in zephyr/boards/nxp/frdm_mcxe31b/frdm_mcxe31b-pinctrl.dtsi:23 */
			group2 {
				pinmux = < 0x836008 >; /* in zephyr/boards/nxp/frdm_mcxe31b/frdm_mcxe31b-pinctrl.dtsi:24 */
				input-enable;          /* in zephyr/boards/nxp/frdm_mcxe31b/frdm_mcxe31b-pinctrl.dtsi:25 */
			};
		};
	};

	/* node '/leds' defined in zephyr/boards/nxp/frdm_mcxe31b/frdm_mcxe31b.dts:37 */
	leds {
		compatible = "gpio-leds"; /* in zephyr/boards/nxp/frdm_mcxe31b/frdm_mcxe31b.dts:38 */

		/* node '/leds/led_0' defined in zephyr/boards/nxp/frdm_mcxe31b/frdm_mcxe31b.dts:40 */
		red_led: led_0 {
			gpios = < &gpioc_h 0x0 0x1 >; /* in zephyr/boards/nxp/frdm_mcxe31b/frdm_mcxe31b.dts:41 */
			label = "Red LED";            /* in zephyr/boards/nxp/frdm_mcxe31b/frdm_mcxe31b.dts:42 */
		};

		/* node '/leds/led_1' defined in zephyr/boards/nxp/frdm_mcxe31b/frdm_mcxe31b.dts:45 */
		green_led: led_1 {
			gpios = < &gpiob_h 0x6 0x1 >; /* in zephyr/boards/nxp/frdm_mcxe31b/frdm_mcxe31b.dts:46 */
			label = "Green LED";          /* in zephyr/boards/nxp/frdm_mcxe31b/frdm_mcxe31b.dts:47 */
		};

		/* node '/leds/led_2' defined in zephyr/boards/nxp/frdm_mcxe31b/frdm_mcxe31b.dts:50 */
		blue_led: led_2 {
			gpios = < &gpioc_l 0xe 0x1 >; /* in zephyr/boards/nxp/frdm_mcxe31b/frdm_mcxe31b.dts:51 */
			label = "Blue LED";           /* in zephyr/boards/nxp/frdm_mcxe31b/frdm_mcxe31b.dts:52 */
		};
	};

	/* node '/gpio_keys' defined in zephyr/boards/nxp/frdm_mcxe31b/frdm_mcxe31b.dts:56 */
	gpio_keys {
		compatible = "gpio-keys"; /* in zephyr/boards/nxp/frdm_mcxe31b/frdm_mcxe31b.dts:57 */

		/* node '/gpio_keys/button_0' defined in zephyr/boards/nxp/frdm_mcxe31b/frdm_mcxe31b.dts:59 */
		user_button: button_0 {
			label = "User SW3";           /* in zephyr/boards/nxp/frdm_mcxe31b/frdm_mcxe31b.dts:60 */
			gpios = < &gpiod_l 0x5 0x1 >; /* in zephyr/boards/nxp/frdm_mcxe31b/frdm_mcxe31b.dts:61 */
			zephyr,code = < 0xb >;        /* in zephyr/boards/nxp/frdm_mcxe31b/frdm_mcxe31b.dts:62 */
		};
	};

	/* node '/connector' defined in zephyr/boards/nxp/frdm_mcxe31b/frdm_mcxe31b.dts:66 */
	arduino_header: connector {
		compatible = "arduino-header-r3";          /* in zephyr/boards/nxp/frdm_mcxe31b/frdm_mcxe31b.dts:67 */
		#gpio-cells = < 0x2 >;                     /* in zephyr/boards/nxp/frdm_mcxe31b/frdm_mcxe31b.dts:68 */
		gpio-map-mask = < 0xffffffff 0xffffffc0 >; /* in zephyr/boards/nxp/frdm_mcxe31b/frdm_mcxe31b.dts:69 */
		gpio-map-pass-thru = < 0x0 0x3f >;         /* in zephyr/boards/nxp/frdm_mcxe31b/frdm_mcxe31b.dts:70 */
		gpio-map = < 0x0 0x0 &gpioe_h 0x0 0x0 >,
		           < 0x1 0x0 &gpioe_l 0xf 0x0 >,
		           < 0x2 0x0 &gpiod_l 0x1 0x0 >,
		           < 0x3 0x0 &gpioe_l 0xa 0x0 >,
		           < 0x4 0x0 &gpioc_l 0xb 0x0 >,
		           < 0x5 0x0 &gpioc_l 0xa 0x0 >,
		           < 0x6 0x0 &gpioa_l 0x8 0x0 >,
		           < 0x7 0x0 &gpioa_l 0x9 0x0 >,
		           < 0x8 0x0 &gpioe_h 0x7 0x0 >,
		           < 0x9 0x0 &gpioa_l 0xd 0x0 >,
		           < 0xa 0x0 &gpioe_h 0x6 0x0 >,
		           < 0xb 0x0 &gpioe_h 0x5 0x0 >,
		           < 0xc 0x0 &gpioa_h 0x0 0x0 >,
		           < 0xd 0x0 &gpioe_h 0x1 0x0 >,
		           < 0xe 0x0 &gpioe_h 0x2 0x0 >,
		           < 0xf 0x0 &gpioa_l 0xf 0x0 >,
		           < 0x10 0x0 &gpioe_l 0x6 0x0 >,
		           < 0x11 0x0 &gpioe_l 0x2 0x0 >,
		           < 0x12 0x0 &gpioe_l 0x0 0x0 >,
		           < 0x13 0x0 &gpioe_l 0x1 0x0 >,
		           < 0x14 0x0 &gpioc_l 0x6 0x0 >,
		           < 0x15 0x0 &gpioc_l 0x7 0x0 >;  /* in zephyr/boards/nxp/frdm_mcxe31b/frdm_mcxe31b.dts:71 */
	};
};
